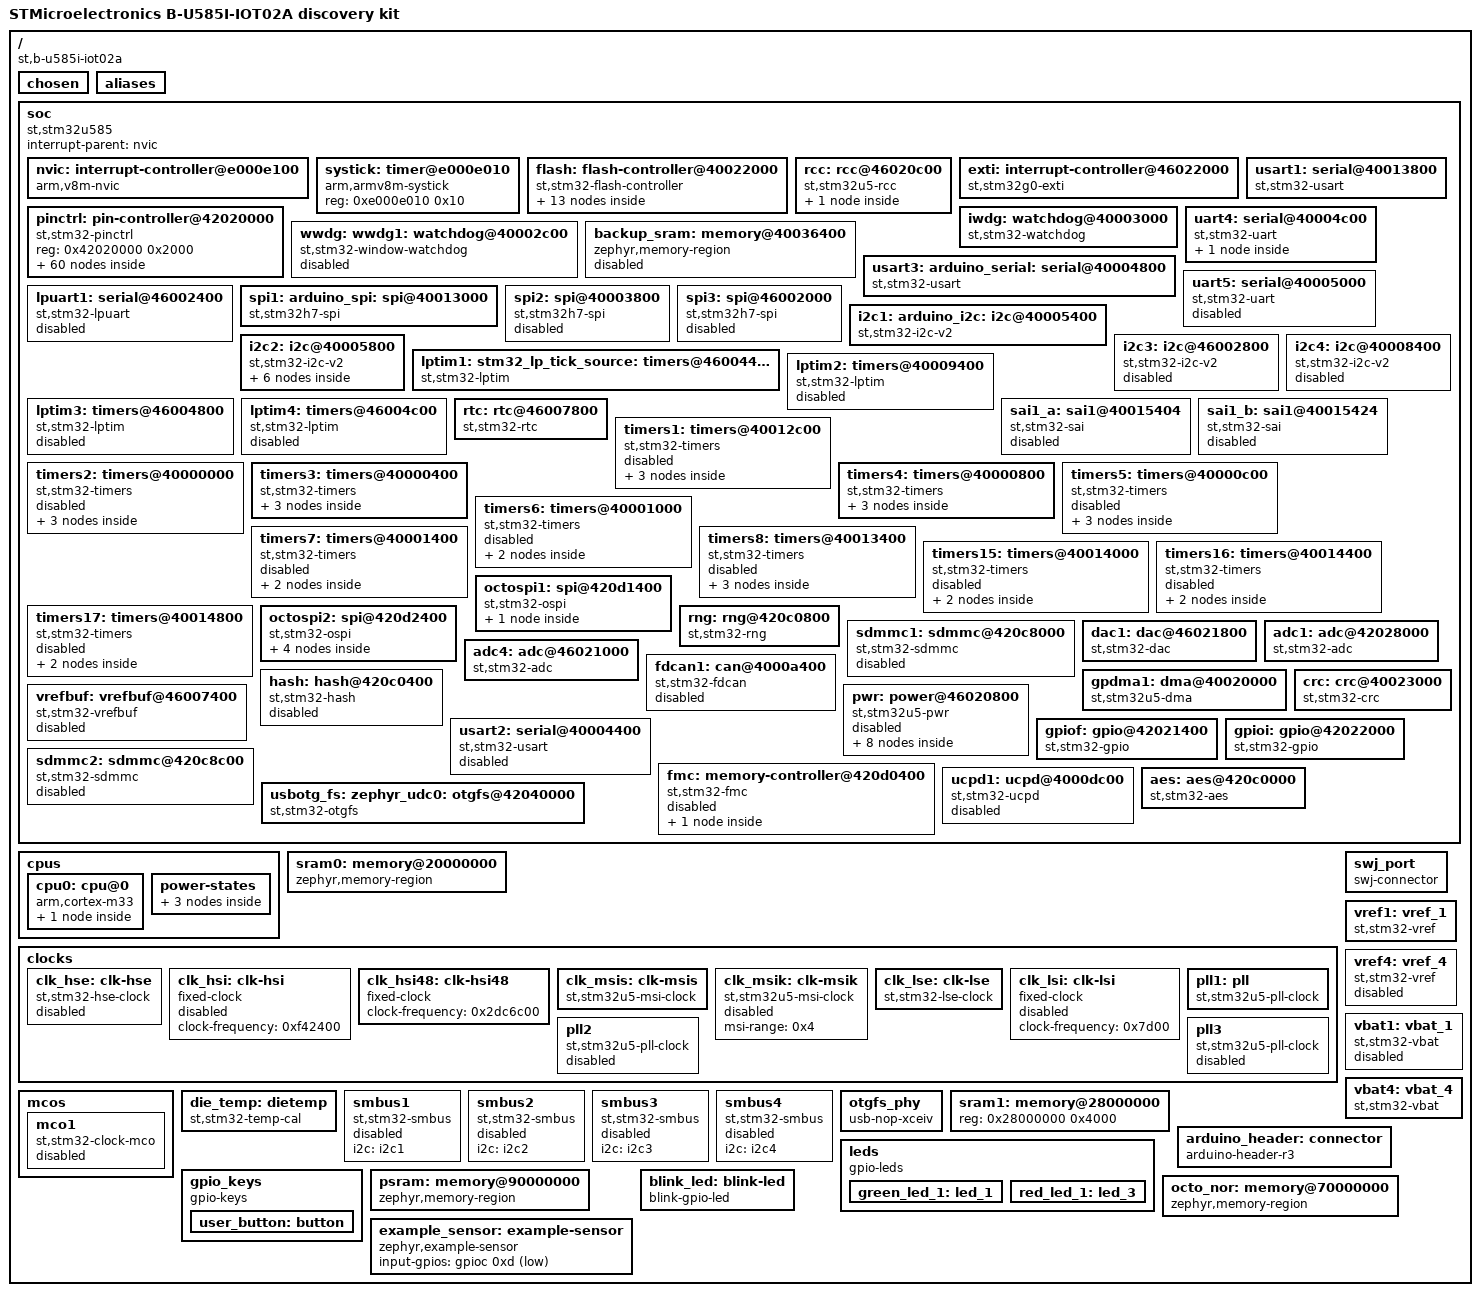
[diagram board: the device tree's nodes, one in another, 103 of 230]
/dts-v1/;

/* node '/' defined in zephyr/dts/common/skeleton.dtsi:9 */
/ {
	#address-cells = < 0x1 >;                                  /* in zephyr/dts/common/skeleton.dtsi:10 */
	#size-cells = < 0x1 >;                                     /* in zephyr/dts/common/skeleton.dtsi:11 */
	model = "STMicroelectronics B-U585I-IOT02A discovery kit"; /* in zephyr/boards/st/b_u585i_iot02a/b_u585i_iot02a.dts:13 */
	compatible = "st,b-u585i-iot02a";                          /* in zephyr/boards/st/b_u585i_iot02a/b_u585i_iot02a.dts:14 */

	/* node '/chosen' defined in zephyr/dts/common/skeleton.dtsi:13 */
	chosen {
		zephyr,crc = &crc;                        /* in zephyr/dts/arm/st/u5/stm32u5.dtsi:27 */
		zephyr,entropy = &rng;                    /* in zephyr/dts/arm/st/u5/stm32u5.dtsi:28 */
		zephyr,flash-controller = &flash;         /* in zephyr/dts/arm/st/u5/stm32u5.dtsi:29 */
		zephyr,console = &usart1;                 /* in zephyr/boards/st/b_u585i_iot02a/b_u585i_iot02a.dts:17 */
		zephyr,shell-uart = &usart1;              /* in zephyr/boards/st/b_u585i_iot02a/b_u585i_iot02a.dts:18 */
		zephyr,sram = &sram0;                     /* in zephyr/boards/st/b_u585i_iot02a/b_u585i_iot02a.dts:19 */
		zephyr,flash = &flash0;                   /* in zephyr/boards/st/b_u585i_iot02a/b_u585i_iot02a.dts:20 */
		zephyr,code-partition = &slot0_partition; /* in zephyr/boards/st/b_u585i_iot02a/b_u585i_iot02a.dts:21 */
		zephyr,bt-hci = &bt_hci_uart;             /* in zephyr/boards/st/b_u585i_iot02a/b_u585i_iot02a.dts:22 */
	};

	/* node '/aliases' defined in zephyr/dts/common/skeleton.dtsi:15 */
	aliases {
		watchdog0 = &iwdg;     /* in zephyr/boards/st/b_u585i_iot02a/b_u585i_iot02a-common.dtsi:41 */
		volt-sensor0 = &vref1; /* in zephyr/boards/st/b_u585i_iot02a/b_u585i_iot02a-common.dtsi:43 */
		volt-sensor1 = &vbat4; /* in zephyr/boards/st/b_u585i_iot02a/b_u585i_iot02a-common.dtsi:44 */
		eeprom-0 = &eeprom0;   /* in zephyr/boards/st/b_u585i_iot02a/b_u585i_iot02a-common.dtsi:45 */
		led0 = &green_led_1;   /* in zephyr/boards/st/b_u585i_iot02a/b_u585i_iot02a.dts:26 */
		led1 = &red_led_1;     /* in zephyr/boards/st/b_u585i_iot02a/b_u585i_iot02a.dts:27 */
		rtc = &rtc;            /* in zephyr/boards/st/b_u585i_iot02a/b_u585i_iot02a.dts:28 */
		sw0 = &user_button;    /* in zephyr/boards/st/b_u585i_iot02a/b_u585i_iot02a.dts:29 */
		die-temp0 = &die_temp; /* in zephyr/boards/st/b_u585i_iot02a/b_u585i_iot02a.dts:30 */
	};

	/* node '/soc' defined in zephyr/dts/arm/armv8-m.dtsi:6 */
	soc {
		#address-cells = < 0x1 >;     /* in zephyr/dts/arm/armv8-m.dtsi:7 */
		#size-cells = < 0x1 >;        /* in zephyr/dts/arm/armv8-m.dtsi:8 */
		interrupt-parent = < &nvic >; /* in zephyr/dts/arm/armv8-m.dtsi:10 */
		ranges;                       /* in zephyr/dts/arm/armv8-m.dtsi:11 */
		compatible = "st,stm32u585",
		             "st,stm32u5",
		             "simple-bus";    /* in zephyr/dts/arm/st/u5/stm32u585.dtsi:13 */

		/* node '/soc/interrupt-controller@e000e100' defined in zephyr/dts/arm/armv8-m.dtsi:13 */
		nvic: interrupt-controller@e000e100 {
			#address-cells = < 0x1 >;            /* in zephyr/dts/arm/armv8-m.dtsi:14 */
			compatible = "arm,v8m-nvic";         /* in zephyr/dts/arm/armv8-m.dtsi:15 */
			reg = < 0xe000e100 0xc00 >;          /* in zephyr/dts/arm/armv8-m.dtsi:16 */
			interrupt-controller;                /* in zephyr/dts/arm/armv8-m.dtsi:17 */
			#interrupt-cells = < 0x2 >;          /* in zephyr/dts/arm/armv8-m.dtsi:18 */
			arm,num-irq-priority-bits = < 0x4 >; /* in zephyr/dts/arm/st/u5/stm32u5.dtsi:1148 */
			phandle = < 0x1 >;                   /* in zephyr/dts/arm/armv8-m.dtsi:10 */
		};

		/* node '/soc/timer@e000e010' defined in zephyr/dts/arm/armv8-m.dtsi:21 */
		systick: timer@e000e010 {
			compatible = "arm,armv8m-systick"; /* in zephyr/dts/arm/armv8-m.dtsi:22 */
			reg = < 0xe000e010 0x10 >;         /* in zephyr/dts/arm/armv8-m.dtsi:23 */
		};

		/* node '/soc/flash-controller@40022000' defined in zephyr/dts/arm/st/u5/stm32u5.dtsi:165 */
		flash: flash-controller@40022000 {
			compatible = "st,stm32-flash-controller",
			             "st,stm32l5-flash-controller"; /* in zephyr/dts/arm/st/u5/stm32u5.dtsi:166 */
			reg = < 0x40022000 0x400 >;                 /* in zephyr/dts/arm/st/u5/stm32u5.dtsi:167 */
			interrupts = < 0x6 0x0 >;                   /* in zephyr/dts/arm/st/u5/stm32u5.dtsi:168 */
			#address-cells = < 0x1 >;                   /* in zephyr/dts/arm/st/u5/stm32u5.dtsi:170 */
			#size-cells = < 0x1 >;                      /* in zephyr/dts/arm/st/u5/stm32u5.dtsi:171 */
			ranges;                                     /* in zephyr/dts/arm/st/u5/stm32u5.dtsi:172 */

			/* node '/soc/flash-controller@40022000/flash@8000000' defined in zephyr/dts/arm/st/u5/stm32u5.dtsi:174 */
			flash0: flash@8000000 {
				compatible = "st,stm32-nv-flash",
				             "soc-nv-flash";         /* in zephyr/dts/arm/st/u5/stm32u5.dtsi:175 */
				#address-cells = < 0x1 >;            /* in zephyr/dts/arm/st/u5/stm32u5.dtsi:176 */
				#size-cells = < 0x1 >;               /* in zephyr/dts/arm/st/u5/stm32u5.dtsi:177 */
				write-block-size = < 0x10 >;         /* in zephyr/dts/arm/st/u5/stm32u5.dtsi:178 */
				erase-block-size = < 0x2000 >;       /* in zephyr/dts/arm/st/u5/stm32u5.dtsi:179 */
				max-erase-time = < 0x5 >;            /* in zephyr/dts/arm/st/u5/stm32u5.dtsi:181 */
				reg = < 0x8000000 0x200000 >;        /* in zephyr/dts/arm/st/u5/stm32u585Xi.dtsi:13 */
				ranges = < 0x0 0x8000000 0x200000 >; /* in zephyr/dts/arm/st/u5/stm32u585Xi.dtsi:14 */

				/* node '/soc/flash-controller@40022000/flash@8000000/partitions' defined in zephyr/boards/st/b_u585i_iot02a/b_u585i_iot02a.dts:43 */
				partitions {
					#address-cells = < 0x1 >; /* in zephyr/boards/st/b_u585i_iot02a/b_u585i_iot02a.dts:44 */
					#size-cells = < 0x1 >;    /* in zephyr/boards/st/b_u585i_iot02a/b_u585i_iot02a.dts:45 */
					ranges;                   /* in zephyr/boards/st/b_u585i_iot02a/b_u585i_iot02a.dts:46 */

					/* node '/soc/flash-controller@40022000/flash@8000000/partitions/partition@0' defined in zephyr/boards/st/b_u585i_iot02a/b_u585i_iot02a.dts:53 */
					boot_partition: partition@0 {
						compatible = "zephyr,mapped-partition"; /* in zephyr/boards/st/b_u585i_iot02a/b_u585i_iot02a.dts:54 */
						label = "mcuboot";                      /* in zephyr/boards/st/b_u585i_iot02a/b_u585i_iot02a.dts:55 */
						reg = < 0x0 0x10000 >;                  /* in zephyr/boards/st/b_u585i_iot02a/b_u585i_iot02a.dts:56 */
					};

					/* node '/soc/flash-controller@40022000/flash@8000000/partitions/partition@10000' defined in zephyr/boards/st/b_u585i_iot02a/b_u585i_iot02a.dts:59 */
					slot0_partition: partition@10000 {
						compatible = "zephyr,mapped-partition"; /* in zephyr/boards/st/b_u585i_iot02a/b_u585i_iot02a.dts:60 */
						label = "image-0";                      /* in zephyr/boards/st/b_u585i_iot02a/b_u585i_iot02a.dts:61 */
						reg = < 0x10000 0x68000 >;              /* in zephyr/boards/st/b_u585i_iot02a/b_u585i_iot02a.dts:62 */
					};

					/* node '/soc/flash-controller@40022000/flash@8000000/partitions/partition@78000' defined in zephyr/boards/st/b_u585i_iot02a/b_u585i_iot02a.dts:65 */
					slot1_partition: partition@78000 {
						compatible = "zephyr,mapped-partition"; /* in zephyr/boards/st/b_u585i_iot02a/b_u585i_iot02a.dts:66 */
						label = "image-1";                      /* in zephyr/boards/st/b_u585i_iot02a/b_u585i_iot02a.dts:67 */
						reg = < 0x78000 0x68000 >;              /* in zephyr/boards/st/b_u585i_iot02a/b_u585i_iot02a.dts:68 */
					};

					/* node '/soc/flash-controller@40022000/flash@8000000/partitions/partition@e0000' defined in zephyr/boards/st/b_u585i_iot02a/b_u585i_iot02a.dts:71 */
					scratch_partition: partition@e0000 {
						compatible = "zephyr,mapped-partition"; /* in zephyr/boards/st/b_u585i_iot02a/b_u585i_iot02a.dts:72 */
						label = "image-scratch";                /* in zephyr/boards/st/b_u585i_iot02a/b_u585i_iot02a.dts:73 */
						reg = < 0xe0000 0x10000 >;              /* in zephyr/boards/st/b_u585i_iot02a/b_u585i_iot02a.dts:74 */
					};

					/* node '/soc/flash-controller@40022000/flash@8000000/partitions/partition@f0000' defined in zephyr/boards/st/b_u585i_iot02a/b_u585i_iot02a.dts:77 */
					storage_partition: partition@f0000 {
						compatible = "zephyr,mapped-partition"; /* in zephyr/boards/st/b_u585i_iot02a/b_u585i_iot02a.dts:78 */
						label = "storage";                      /* in zephyr/boards/st/b_u585i_iot02a/b_u585i_iot02a.dts:79 */
						reg = < 0xf0000 0x10000 >;              /* in zephyr/boards/st/b_u585i_iot02a/b_u585i_iot02a.dts:80 */
					};
				};
			};

			/* node '/soc/flash-controller@40022000/flash@bfa0000' defined in zephyr/dts/arm/st/u5/stm32u5.dtsi:184 */
			st_nvm_user_otp: flash@bfa0000 {
				compatible = "st,stm32-nvm-otp"; /* in zephyr/dts/arm/st/u5/stm32u5.dtsi:185 */
				reg = < 0xbfa0000 0x200 >;       /* in zephyr/dts/arm/st/u5/stm32u5.dtsi:186 */
				status = "disabled";             /* in zephyr/dts/arm/st/u5/stm32u5.dtsi:187 */
			};

			/* node '/soc/flash-controller@40022000/flash@bfa0500' defined in zephyr/dts/arm/st/u5/stm32u5.dtsi:191 */
			flash@bfa0500 {
				compatible = "st,stm32-nvm-otp"; /* in zephyr/dts/arm/st/u5/stm32u5.dtsi:192 */
				reg = < 0xbfa0500 0x1b00 >;      /* in zephyr/dts/arm/st/u5/stm32u5.dtsi:193 */

				/* node '/soc/flash-controller@40022000/flash@bfa0500/nvmem-layout' defined in zephyr/dts/arm/st/u5/stm32u5.dtsi:195 */
				nvmem-layout {
					compatible = "fixed-layout"; /* in zephyr/dts/arm/st/u5/stm32u5.dtsi:196 */
					#address-cells = < 0x1 >;    /* in zephyr/dts/arm/st/u5/stm32u5.dtsi:197 */
					#size-cells = < 0x1 >;       /* in zephyr/dts/arm/st/u5/stm32u5.dtsi:198 */

					/* node '/soc/flash-controller@40022000/flash@bfa0500/nvmem-layout/ts-cal1@210' defined in zephyr/dts/arm/st/u5/stm32u5.dtsi:200 */
					ts_cal1_otp: ts-cal1@210 {
						reg = < 0x210 0x2 >;         /* in zephyr/dts/arm/st/u5/stm32u5.dtsi:201 */
						#nvmem-cell-cells = < 0x0 >; /* in zephyr/dts/arm/st/u5/stm32u5.dtsi:202 */
						read-only;                   /* in zephyr/dts/arm/st/u5/stm32u5.dtsi:203 */
						phandle = < 0x47 >;          /* in zephyr/dts/arm/st/u5/stm32u5.dtsi:1072 */
					};

					/* node '/soc/flash-controller@40022000/flash@bfa0500/nvmem-layout/ts-cal2@242' defined in zephyr/dts/arm/st/u5/stm32u5.dtsi:206 */
					ts_cal2_otp: ts-cal2@242 {
						reg = < 0x242 0x2 >;         /* in zephyr/dts/arm/st/u5/stm32u5.dtsi:207 */
						#nvmem-cell-cells = < 0x0 >; /* in zephyr/dts/arm/st/u5/stm32u5.dtsi:208 */
						read-only;                   /* in zephyr/dts/arm/st/u5/stm32u5.dtsi:209 */
						phandle = < 0x48 >;          /* in zephyr/dts/arm/st/u5/stm32u5.dtsi:1072 */
					};

					/* node '/soc/flash-controller@40022000/flash@bfa0500/nvmem-layout/vrefint@2a5' defined in zephyr/dts/arm/st/u5/stm32u5.dtsi:212 */
					vrefint_otp: vrefint@2a5 {
						reg = < 0x2a5 0x2 >;         /* in zephyr/dts/arm/st/u5/stm32u5.dtsi:213 */
						#nvmem-cell-cells = < 0x0 >; /* in zephyr/dts/arm/st/u5/stm32u5.dtsi:214 */
						read-only;                   /* in zephyr/dts/arm/st/u5/stm32u5.dtsi:215 */
						phandle = < 0x4a >;          /* in zephyr/dts/arm/st/u5/stm32u5.dtsi:1084 */
					};
				};
			};
		};

		/* node '/soc/rcc@46020c00' defined in zephyr/dts/arm/st/u5/stm32u5.dtsi:221 */
		rcc: rcc@46020c00 {
			compatible = "st,stm32u5-rcc";   /* in zephyr/dts/arm/st/u5/stm32u5.dtsi:222 */
			clocks-controller;               /* in zephyr/dts/arm/st/u5/stm32u5.dtsi:223 */
			#clock-cells = < 0x2 >;          /* in zephyr/dts/arm/st/u5/stm32u5.dtsi:224 */
			reg = < 0x46020c00 0x400 >;      /* in zephyr/dts/arm/st/u5/stm32u5.dtsi:225 */
			clocks = < &pll1 >;              /* in zephyr/boards/st/b_u585i_iot02a/b_u585i_iot02a-common.dtsi:80 */
			clock-frequency = < 0x9896800 >; /* in zephyr/boards/st/b_u585i_iot02a/b_u585i_iot02a-common.dtsi:81 */
			ahb-prescaler = < 0x1 >;         /* in zephyr/boards/st/b_u585i_iot02a/b_u585i_iot02a-common.dtsi:82 */
			apb1-prescaler = < 0x1 >;        /* in zephyr/boards/st/b_u585i_iot02a/b_u585i_iot02a-common.dtsi:83 */
			apb2-prescaler = < 0x1 >;        /* in zephyr/boards/st/b_u585i_iot02a/b_u585i_iot02a-common.dtsi:84 */
			apb3-prescaler = < 0x1 >;        /* in zephyr/boards/st/b_u585i_iot02a/b_u585i_iot02a-common.dtsi:85 */
			phandle = < 0x3 >;               /* in zephyr/dts/arm/st/u5/stm32u5.dtsi:239 */

			/* node '/soc/rcc@46020c00/reset-controller' defined in zephyr/dts/arm/st/u5/stm32u5.dtsi:227 */
			rctl: reset-controller {
				compatible = "st,stm32-rcc-rctl"; /* in zephyr/dts/arm/st/u5/stm32u5.dtsi:228 */
				#reset-cells = < 0x1 >;           /* in zephyr/dts/arm/st/u5/stm32u5.dtsi:229 */
				phandle = < 0x4 >;                /* in zephyr/dts/arm/st/u5/stm32u5.dtsi:346 */
			};
		};

		/* node '/soc/interrupt-controller@46022000' defined in zephyr/dts/arm/st/u5/stm32u5.dtsi:233 */
		exti: interrupt-controller@46022000 {
			compatible = "st,stm32g0-exti",
			             "st,stm32-exti";   /* in zephyr/dts/arm/st/u5/stm32u5.dtsi:234 */
			interrupt-controller;           /* in zephyr/dts/arm/st/u5/stm32u5.dtsi:235 */
			#interrupt-cells = < 0x1 >;     /* in zephyr/dts/arm/st/u5/stm32u5.dtsi:236 */
			#address-cells = < 0x0 >;       /* in zephyr/dts/arm/st/u5/stm32u5.dtsi:237 */
			reg = < 0x46022000 0x400 >;     /* in zephyr/dts/arm/st/u5/stm32u5.dtsi:238 */
			clocks = < &rcc 0xa8 0x2 >;     /* in zephyr/dts/arm/st/u5/stm32u5.dtsi:239 */
			num-lines = < 0x20 >;           /* in zephyr/dts/arm/st/u5/stm32u5.dtsi:240 */
			interrupts = < 0xb 0x0 >,
			             < 0xc 0x0 >,
			             < 0xd 0x0 >,
			             < 0xe 0x0 >,
			             < 0xf 0x0 >,
			             < 0x10 0x0 >,
			             < 0x11 0x0 >,
			             < 0x12 0x0 >,
			             < 0x13 0x0 >,
			             < 0x14 0x0 >,
			             < 0x15 0x0 >,
			             < 0x16 0x0 >,
			             < 0x17 0x0 >,
			             < 0x18 0x0 >,
			             < 0x19 0x0 >,
			             < 0x1a 0x0 >;      /* in zephyr/dts/arm/st/u5/stm32u5.dtsi:241 */
			interrupt-names = "line0",
			                  "line1",
			                  "line2",
			                  "line3",
			                  "line4",
			                  "line5",
			                  "line6",
			                  "line7",
			                  "line8",
			                  "line9",
			                  "line10",
			                  "line11",
			                  "line12",
			                  "line13",
			                  "line14",
			                  "line15";     /* in zephyr/dts/arm/st/u5/stm32u5.dtsi:245 */
			line-ranges = < 0x0 0x1 >,
			              < 0x1 0x1 >,
			              < 0x2 0x1 >,
			              < 0x3 0x1 >,
			              < 0x4 0x1 >,
			              < 0x5 0x1 >,
			              < 0x6 0x1 >,
			              < 0x7 0x1 >,
			              < 0x8 0x1 >,
			              < 0x9 0x1 >,
			              < 0xa 0x1 >,
			              < 0xb 0x1 >,
			              < 0xc 0x1 >,
			              < 0xd 0x1 >,
			              < 0xe 0x1 >,
			              < 0xf 0x1 >;      /* in zephyr/dts/arm/st/u5/stm32u5.dtsi:249 */
		};

		/* node '/soc/pin-controller@42020000' defined in zephyr/dts/arm/st/u5/stm32u5.dtsi:255 */
		pinctrl: pin-controller@42020000 {
			compatible = "st,stm32-pinctrl"; /* in zephyr/dts/arm/st/u5/stm32u5.dtsi:256 */
			#address-cells = < 0x1 >;        /* in zephyr/dts/arm/st/u5/stm32u5.dtsi:257 */
			#size-cells = < 0x1 >;           /* in zephyr/dts/arm/st/u5/stm32u5.dtsi:258 */
			reg = < 0x42020000 0x2000 >;     /* in zephyr/dts/arm/st/u5/stm32u5.dtsi:259 */

			/* node '/soc/pin-controller@42020000/gpio@42020000' defined in zephyr/dts/arm/st/u5/stm32u5.dtsi:261 */
			gpioa: gpio@42020000 {
				compatible = "st,stm32-gpio"; /* in zephyr/dts/arm/st/u5/stm32u5.dtsi:262 */
				gpio-controller;              /* in zephyr/dts/arm/st/u5/stm32u5.dtsi:263 */
				#gpio-cells = < 0x2 >;        /* in zephyr/dts/arm/st/u5/stm32u5.dtsi:264 */
				reg = < 0x42020000 0x400 >;   /* in zephyr/dts/arm/st/u5/stm32u5.dtsi:265 */
				clocks = < &rcc 0x8c 0x1 >;   /* in zephyr/dts/arm/st/u5/stm32u5.dtsi:266 */
				phandle = < 0x32 >;           /* in zephyr/dts/arm/st/u5/stm32u5.dtsi:997 */
			};

			/* node '/soc/pin-controller@42020000/gpio@42020400' defined in zephyr/dts/arm/st/u5/stm32u5.dtsi:269 */
			gpiob: gpio@42020400 {
				compatible = "st,stm32-gpio"; /* in zephyr/dts/arm/st/u5/stm32u5.dtsi:270 */
				gpio-controller;              /* in zephyr/dts/arm/st/u5/stm32u5.dtsi:271 */
				#gpio-cells = < 0x2 >;        /* in zephyr/dts/arm/st/u5/stm32u5.dtsi:272 */
				reg = < 0x42020400 0x400 >;   /* in zephyr/dts/arm/st/u5/stm32u5.dtsi:273 */
				clocks = < &rcc 0x8c 0x2 >;   /* in zephyr/dts/arm/st/u5/stm32u5.dtsi:274 */
				phandle = < 0x33 >;           /* in zephyr/dts/arm/st/u5/stm32u5.dtsi:997 */
			};

			/* node '/soc/pin-controller@42020000/gpio@42020800' defined in zephyr/dts/arm/st/u5/stm32u5.dtsi:277 */
			gpioc: gpio@42020800 {
				compatible = "st,stm32-gpio"; /* in zephyr/dts/arm/st/u5/stm32u5.dtsi:278 */
				gpio-controller;              /* in zephyr/dts/arm/st/u5/stm32u5.dtsi:279 */
				#gpio-cells = < 0x2 >;        /* in zephyr/dts/arm/st/u5/stm32u5.dtsi:280 */
				reg = < 0x42020800 0x400 >;   /* in zephyr/dts/arm/st/u5/stm32u5.dtsi:281 */
				clocks = < &rcc 0x8c 0x4 >;   /* in zephyr/dts/arm/st/u5/stm32u5.dtsi:282 */
				status = "okay";              /* in my-app/app/boards/b_u585i_iot02a.overlay:26 */
				phandle = < 0x34 >;           /* in zephyr/dts/arm/st/u5/stm32u5.dtsi:1004 */
			};

			/* node '/soc/pin-controller@42020000/gpio@42020c00' defined in zephyr/dts/arm/st/u5/stm32u5.dtsi:285 */
			gpiod: gpio@42020c00 {
				compatible = "st,stm32-gpio"; /* in zephyr/dts/arm/st/u5/stm32u5.dtsi:286 */
				gpio-controller;              /* in zephyr/dts/arm/st/u5/stm32u5.dtsi:287 */
				#gpio-cells = < 0x2 >;        /* in zephyr/dts/arm/st/u5/stm32u5.dtsi:288 */
				reg = < 0x42020c00 0x400 >;   /* in zephyr/dts/arm/st/u5/stm32u5.dtsi:289 */
				clocks = < &rcc 0x8c 0x8 >;   /* in zephyr/dts/arm/st/u5/stm32u5.dtsi:290 */
				phandle = < 0x13 >;           /* in zephyr/boards/st/b_u585i_iot02a/b_u585i_iot02a-common.dtsi:217 */
			};

			/* node '/soc/pin-controller@42020000/gpio@42021000' defined in zephyr/dts/arm/st/u5/stm32u5.dtsi:293 */
			gpioe: gpio@42021000 {
				compatible = "st,stm32-gpio"; /* in zephyr/dts/arm/st/u5/stm32u5.dtsi:294 */
				gpio-controller;              /* in zephyr/dts/arm/st/u5/stm32u5.dtsi:295 */
				#gpio-cells = < 0x2 >;        /* in zephyr/dts/arm/st/u5/stm32u5.dtsi:296 */
				reg = < 0x42021000 0x400 >;   /* in zephyr/dts/arm/st/u5/stm32u5.dtsi:297 */
				clocks = < &rcc 0x8c 0x10 >;  /* in zephyr/dts/arm/st/u5/stm32u5.dtsi:298 */
				phandle = < 0x14 >;           /* in zephyr/boards/st/b_u585i_iot02a/b_u585i_iot02a-common.dtsi:223 */
			};

			/* node '/soc/pin-controller@42020000/gpio@42021800' defined in zephyr/dts/arm/st/u5/stm32u5.dtsi:301 */
			gpiog: gpio@42021800 {
				compatible = "st,stm32-gpio"; /* in zephyr/dts/arm/st/u5/stm32u5.dtsi:302 */
				gpio-controller;              /* in zephyr/dts/arm/st/u5/stm32u5.dtsi:303 */
				#gpio-cells = < 0x2 >;        /* in zephyr/dts/arm/st/u5/stm32u5.dtsi:304 */
				reg = < 0x42021800 0x400 >;   /* in zephyr/dts/arm/st/u5/stm32u5.dtsi:305 */
				clocks = < &rcc 0x8c 0x40 >;  /* in zephyr/dts/arm/st/u5/stm32u5.dtsi:306 */
				phandle = < 0x15 >;           /* in zephyr/boards/st/b_u585i_iot02a/b_u585i_iot02a-common.dtsi:229 */
			};

			/* node '/soc/pin-controller@42020000/gpio@42021c00' defined in zephyr/dts/arm/st/u5/stm32u5.dtsi:309 */
			gpioh: gpio@42021c00 {
				compatible = "st,stm32-gpio"; /* in zephyr/dts/arm/st/u5/stm32u5.dtsi:310 */
				gpio-controller;              /* in zephyr/dts/arm/st/u5/stm32u5.dtsi:311 */
				#gpio-cells = < 0x2 >;        /* in zephyr/dts/arm/st/u5/stm32u5.dtsi:312 */
				reg = < 0x42021c00 0x400 >;   /* in zephyr/dts/arm/st/u5/stm32u5.dtsi:313 */
				clocks = < &rcc 0x8c 0x80 >;  /* in zephyr/dts/arm/st/u5/stm32u5.dtsi:314 */
				phandle = < 0x50 >;           /* in zephyr/boards/st/b_u585i_iot02a/b_u585i_iot02a-common.dtsi:20 */
			};

			/* node '/soc/pin-controller@42020000/adc1_in15_pb0' defined in modules/hal/stm32/dts/st/u5/stm32u585aiixq-pinctrl.dtsi:45 */
			adc1_in15_pb0: adc1_in15_pb0 {
				pinmux = < 0x210 >; /* in modules/hal/stm32/dts/st/u5/stm32u585aiixq-pinctrl.dtsi:46 */
				phandle = < 0x30 >; /* in zephyr/boards/st/b_u585i_iot02a/b_u585i_iot02a-common.dtsi:259 */
			};

			/* node '/soc/pin-controller@42020000/adc4_in19_pb1' defined in modules/hal/stm32/dts/st/u5/stm32u585aiixq-pinctrl.dtsi:101 */
			adc4_in19_pb1: adc4_in19_pb1 {
				pinmux = < 0x230 >; /* in modules/hal/stm32/dts/st/u5/stm32u585aiixq-pinctrl.dtsi:102 */
				phandle = < 0x31 >; /* in zephyr/boards/st/b_u585i_iot02a/b_u585i_iot02a-common.dtsi:267 */
			};

			/* node '/soc/pin-controller@42020000/analog_pa13' defined in modules/hal/stm32/dts/st/u5/stm32u585aiixq-pinctrl.dtsi:211 */
			analog_pa13: analog_pa13 {
				pinmux = < 0x1b0 >; /* in modules/hal/stm32/dts/st/u5/stm32u585aiixq-pinctrl.dtsi:212 */
				phandle = < 0x42 >; /* in zephyr/dts/arm/st/u5/stm32u5.dtsi:1065 */
			};

			/* node '/soc/pin-controller@42020000/analog_pa14' defined in modules/hal/stm32/dts/st/u5/stm32u585aiixq-pinctrl.dtsi:215 */
			analog_pa14: analog_pa14 {
				pinmux = < 0x1d0 >; /* in modules/hal/stm32/dts/st/u5/stm32u585aiixq-pinctrl.dtsi:216 */
				phandle = < 0x43 >; /* in zephyr/dts/arm/st/u5/stm32u5.dtsi:1065 */
			};

			/* node '/soc/pin-controller@42020000/analog_pa15' defined in modules/hal/stm32/dts/st/u5/stm32u585aiixq-pinctrl.dtsi:219 */
			analog_pa15: analog_pa15 {
				pinmux = < 0x1f0 >; /* in modules/hal/stm32/dts/st/u5/stm32u585aiixq-pinctrl.dtsi:220 */
				phandle = < 0x44 >; /* in zephyr/dts/arm/st/u5/stm32u5.dtsi:1065 */
			};

			/* node '/soc/pin-controller@42020000/analog_pb3' defined in modules/hal/stm32/dts/st/u5/stm32u585aiixq-pinctrl.dtsi:235 */
			analog_pb3: analog_pb3 {
				pinmux = < 0x270 >; /* in modules/hal/stm32/dts/st/u5/stm32u585aiixq-pinctrl.dtsi:236 */
				phandle = < 0x45 >; /* in zephyr/dts/arm/st/u5/stm32u5.dtsi:1065 */
			};

			/* node '/soc/pin-controller@42020000/analog_pb4' defined in modules/hal/stm32/dts/st/u5/stm32u585aiixq-pinctrl.dtsi:239 */
			analog_pb4: analog_pb4 {
				pinmux = < 0x290 >; /* in modules/hal/stm32/dts/st/u5/stm32u585aiixq-pinctrl.dtsi:240 */
				phandle = < 0x46 >; /* in zephyr/dts/arm/st/u5/stm32u5.dtsi:1065 */
			};

			/* node '/soc/pin-controller@42020000/dac1_out1_pa4' defined in modules/hal/stm32/dts/st/u5/stm32u585aiixq-pinctrl.dtsi:749 */
			dac1_out1_pa4: dac1_out1_pa4 {
				pinmux = < 0x90 >;  /* in modules/hal/stm32/dts/st/u5/stm32u585aiixq-pinctrl.dtsi:750 */
				phandle = < 0x2f >; /* in zephyr/boards/st/b_u585i_iot02a/b_u585i_iot02a-common.dtsi:279 */
			};

			/* node '/soc/pin-controller@42020000/i2c1_scl_pb8' defined in modules/hal/stm32/dts/st/u5/stm32u585aiixq-pinctrl.dtsi:1405 */
			i2c1_scl_pb8: i2c1_scl_pb8 {
				pinmux = < 0x304 >; /* in modules/hal/stm32/dts/st/u5/stm32u585aiixq-pinctrl.dtsi:1406 */
				bias-pull-up;       /* in modules/hal/stm32/dts/st/u5/stm32u585aiixq-pinctrl.dtsi:1407 */
				drive-open-drain;   /* in modules/hal/stm32/dts/st/u5/stm32u585aiixq-pinctrl.dtsi:1408 */
				phandle = < 0xf >;  /* in zephyr/boards/st/b_u585i_iot02a/b_u585i_iot02a-common.dtsi:196 */
			};

			/* node '/soc/pin-controller@42020000/i2c2_scl_ph4' defined in modules/hal/stm32/dts/st/u5/stm32u585aiixq-pinctrl.dtsi:1429 */
			i2c2_scl_ph4: i2c2_scl_ph4 {
				pinmux = < 0xe84 >; /* in modules/hal/stm32/dts/st/u5/stm32u585aiixq-pinctrl.dtsi:1430 */
				bias-pull-up;       /* in modules/hal/stm32/dts/st/u5/stm32u585aiixq-pinctrl.dtsi:1431 */
				drive-open-drain;   /* in modules/hal/stm32/dts/st/u5/stm32u585aiixq-pinctrl.dtsi:1432 */
				phandle = < 0x11 >; /* in zephyr/boards/st/b_u585i_iot02a/b_u585i_iot02a-common.dtsi:203 */
			};

			/* node '/soc/pin-controller@42020000/i2c1_sda_pb9' defined in modules/hal/stm32/dts/st/u5/stm32u585aiixq-pinctrl.dtsi:1497 */
			i2c1_sda_pb9: i2c1_sda_pb9 {
				pinmux = < 0x324 >; /* in modules/hal/stm32/dts/st/u5/stm32u585aiixq-pinctrl.dtsi:1498 */
				bias-pull-up;       /* in modules/hal/stm32/dts/st/u5/stm32u585aiixq-pinctrl.dtsi:1499 */
				drive-open-drain;   /* in modules/hal/stm32/dts/st/u5/stm32u585aiixq-pinctrl.dtsi:1500 */
				phandle = < 0x10 >; /* in zephyr/boards/st/b_u585i_iot02a/b_u585i_iot02a-common.dtsi:196 */
			};

			/* node '/soc/pin-controller@42020000/i2c2_sda_ph5' defined in modules/hal/stm32/dts/st/u5/stm32u585aiixq-pinctrl.dtsi:1521 */
			i2c2_sda_ph5: i2c2_sda_ph5 {
				pinmux = < 0xea4 >; /* in modules/hal/stm32/dts/st/u5/stm32u585aiixq-pinctrl.dtsi:1522 */
				bias-pull-up;       /* in modules/hal/stm32/dts/st/u5/stm32u585aiixq-pinctrl.dtsi:1523 */
				drive-open-drain;   /* in modules/hal/stm32/dts/st/u5/stm32u585aiixq-pinctrl.dtsi:1524 */
				phandle = < 0x12 >; /* in zephyr/boards/st/b_u585i_iot02a/b_u585i_iot02a-common.dtsi:203 */
			};

			/* node '/soc/pin-controller@42020000/debug_jtms_swdio_pa13' defined in modules/hal/stm32/dts/st/u5/stm32u585aiixq-pinctrl.dtsi:1644 */
			debug_jtms_swdio_pa13: debug_jtms_swdio_pa13 {
				pinmux = < 0x1a0 >; /* in modules/hal/stm32/dts/st/u5/stm32u585aiixq-pinctrl.dtsi:1645 */
				phandle = < 0x3d >; /* in zephyr/dts/arm/st/u5/stm32u5.dtsi:1062 */
			};

			/* node '/soc/pin-controller@42020000/debug_jtck_swclk_pa14' defined in modules/hal/stm32/dts/st/u5/stm32u585aiixq-pinctrl.dtsi:1648 */
			debug_jtck_swclk_pa14: debug_jtck_swclk_pa14 {
				pinmux = < 0x1c0 >; /* in modules/hal/stm32/dts/st/u5/stm32u585aiixq-pinctrl.dtsi:1649 */
				phandle = < 0x3e >; /* in zephyr/dts/arm/st/u5/stm32u5.dtsi:1062 */
			};

			/* node '/soc/pin-controller@42020000/debug_jtdi_pa15' defined in modules/hal/stm32/dts/st/u5/stm32u585aiixq-pinctrl.dtsi:1652 */
			debug_jtdi_pa15: debug_jtdi_pa15 {
				pinmux = < 0x1e0 >; /* in modules/hal/stm32/dts/st/u5/stm32u585aiixq-pinctrl.dtsi:1653 */
				phandle = < 0x3f >; /* in zephyr/dts/arm/st/u5/stm32u5.dtsi:1062 */
			};

			/* node '/soc/pin-controller@42020000/debug_jtdo_swo_pb3' defined in modules/hal/stm32/dts/st/u5/stm32u585aiixq-pinctrl.dtsi:1656 */
			debug_jtdo_swo_pb3: debug_jtdo_swo_pb3 {
				pinmux = < 0x260 >; /* in modules/hal/stm32/dts/st/u5/stm32u585aiixq-pinctrl.dtsi:1657 */
				phandle = < 0x40 >; /* in zephyr/dts/arm/st/u5/stm32u5.dtsi:1062 */
			};

			/* node '/soc/pin-controller@42020000/debug_njtrst_pb4' defined in modules/hal/stm32/dts/st/u5/stm32u585aiixq-pinctrl.dtsi:1660 */
			debug_njtrst_pb4: debug_njtrst_pb4 {
				pinmux = < 0x280 >; /* in modules/hal/stm32/dts/st/u5/stm32u585aiixq-pinctrl.dtsi:1661 */
				phandle = < 0x41 >; /* in zephyr/dts/arm/st/u5/stm32u5.dtsi:1062 */
			};

			/* node '/soc/pin-controller@42020000/octospim_p1_clk_pb10' defined in modules/hal/stm32/dts/st/u5/stm32u585aiixq-pinctrl.dtsi:1944 */
			octospim_p1_clk_pb10: octospim_p1_clk_pb10 {
				pinmux = < 0x34a >;            /* in modules/hal/stm32/dts/st/u5/stm32u585aiixq-pinctrl.dtsi:1945 */
				slew-rate = "very-high-speed"; /* in modules/hal/stm32/dts/st/u5/stm32u585aiixq-pinctrl.dtsi:1946 */
				phandle = < 0x19 >;            /* in zephyr/boards/st/b_u585i_iot02a/b_u585i_iot02a-common.dtsi:138 */
			};

			/* node '/soc/pin-controller@42020000/octospim_p1_ncs_pb11' defined in modules/hal/stm32/dts/st/u5/stm32u585aiixq-pinctrl.dtsi:1949 */
			octospim_p1_ncs_pb11: octospim_p1_ncs_pb11 {
				pinmux = < 0x36a >;            /* in modules/hal/stm32/dts/st/u5/stm32u585aiixq-pinctrl.dtsi:1950 */
				slew-rate = "very-high-speed"; /* in modules/hal/stm32/dts/st/u5/stm32u585aiixq-pinctrl.dtsi:1951 */
				phandle = < 0x1a >;            /* in zephyr/boards/st/b_u585i_iot02a/b_u585i_iot02a-common.dtsi:138 */
			};

			/* node '/soc/pin-controller@42020000/octospim_p1_io6_pc3' defined in modules/hal/stm32/dts/st/u5/stm32u585aiixq-pinctrl.dtsi:1974 */
			octospim_p1_io6_pc3: octospim_p1_io6_pc3 {
				pinmux = < 0x46a >;            /* in modules/hal/stm32/dts/st/u5/stm32u585aiixq-pinctrl.dtsi:1975 */
				slew-rate = "very-high-speed"; /* in modules/hal/stm32/dts/st/u5/stm32u585aiixq-pinctrl.dtsi:1976 */
				phandle = < 0x21 >;            /* in zephyr/boards/st/b_u585i_iot02a/b_u585i_iot02a-common.dtsi:138 */
			};

			/* node '/soc/pin-controller@42020000/octospim_p1_io7_pd7' defined in modules/hal/stm32/dts/st/u5/stm32u585aiixq-pinctrl.dtsi:2009 */
			octospim_p1_io7_pd7: octospim_p1_io7_pd7 {
				pinmux = < 0x6ea >;            /* in modules/hal/stm32/dts/st/u5/stm32u585aiixq-pinctrl.dtsi:2010 */
				slew-rate = "very-high-speed"; /* in modules/hal/stm32/dts/st/u5/stm32u585aiixq-pinctrl.dtsi:2011 */
				phandle = < 0x22 >;            /* in zephyr/boards/st/b_u585i_iot02a/b_u585i_iot02a-common.dtsi:138 */
			};

			/* node '/soc/pin-controller@42020000/octospim_p1_dqs_pe3' defined in modules/hal/stm32/dts/st/u5/stm32u585aiixq-pinctrl.dtsi:2014 */
			octospim_p1_dqs_pe3: octospim_p1_dqs_pe3 {
				pinmux = < 0x863 >;            /* in modules/hal/stm32/dts/st/u5/stm32u585aiixq-pinctrl.dtsi:2015 */
				slew-rate = "very-high-speed"; /* in modules/hal/stm32/dts/st/u5/stm32u585aiixq-pinctrl.dtsi:2016 */
				phandle = < 0x23 >;            /* in zephyr/boards/st/b_u585i_iot02a/b_u585i_iot02a-common.dtsi:138 */
			};

			/* node '/soc/pin-controller@42020000/octospim_p2_io0_pf0' defined in modules/hal/stm32/dts/st/u5/stm32u585aiixq-pinctrl.dtsi:2054 */
			octospim_p2_io0_pf0: octospim_p2_io0_pf0 {
				pinmux = < 0xa05 >;            /* in modules/hal/stm32/dts/st/u5/stm32u585aiixq-pinctrl.dtsi:2055 */
				slew-rate = "very-high-speed"; /* in modules/hal/stm32/dts/st/u5/stm32u585aiixq-pinctrl.dtsi:2056 */
				phandle = < 0x26 >;            /* in zephyr/boards/st/b_u585i_iot02a/b_u585i_iot02a-common.dtsi:161 */
			};

			/* node '/soc/pin-controller@42020000/octospim_p2_io1_pf1' defined in modules/hal/stm32/dts/st/u5/stm32u585aiixq-pinctrl.dtsi:2059 */
			octospim_p2_io1_pf1: octospim_p2_io1_pf1 {
				pinmux = < 0xa25 >;            /* in modules/hal/stm32/dts/st/u5/stm32u585aiixq-pinctrl.dtsi:2060 */
				slew-rate = "very-high-speed"; /* in modules/hal/stm32/dts/st/u5/stm32u585aiixq-pinctrl.dtsi:2061 */
				phandle = < 0x27 >;            /* in zephyr/boards/st/b_u585i_iot02a/b_u585i_iot02a-common.dtsi:161 */
			};

			/* node '/soc/pin-controller@42020000/octospim_p2_io2_pf2' defined in modules/hal/stm32/dts/st/u5/stm32u585aiixq-pinctrl.dtsi:2064 */
			octospim_p2_io2_pf2: octospim_p2_io2_pf2 {
				pinmux = < 0xa45 >;            /* in modules/hal/stm32/dts/st/u5/stm32u585aiixq-pinctrl.dtsi:2065 */
				slew-rate = "very-high-speed"; /* in modules/hal/stm32/dts/st/u5/stm32u585aiixq-pinctrl.dtsi:2066 */
				phandle = < 0x28 >;            /* in zephyr/boards/st/b_u585i_iot02a/b_u585i_iot02a-common.dtsi:161 */
			};

			/* node '/soc/pin-controller@42020000/octospim_p2_io3_pf3' defined in modules/hal/stm32/dts/st/u5/stm32u585aiixq-pinctrl.dtsi:2069 */
			octospim_p2_io3_pf3: octospim_p2_io3_pf3 {
				pinmux = < 0xa65 >;            /* in modules/hal/stm32/dts/st/u5/stm32u585aiixq-pinctrl.dtsi:2070 */
				slew-rate = "very-high-speed"; /* in modules/hal/stm32/dts/st/u5/stm32u585aiixq-pinctrl.dtsi:2071 */
				phandle = < 0x29 >;            /* in zephyr/boards/st/b_u585i_iot02a/b_u585i_iot02a-common.dtsi:161 */
			};

			/* node '/soc/pin-controller@42020000/octospim_p2_clk_pf4' defined in modules/hal/stm32/dts/st/u5/stm32u585aiixq-pinctrl.dtsi:2074 */
			octospim_p2_clk_pf4: octospim_p2_clk_pf4 {
				pinmux = < 0xa85 >;            /* in modules/hal/stm32/dts/st/u5/stm32u585aiixq-pinctrl.dtsi:2075 */
				slew-rate = "very-high-speed"; /* in modules/hal/stm32/dts/st/u5/stm32u585aiixq-pinctrl.dtsi:2076 */
				phandle = < 0x24 >;            /* in zephyr/boards/st/b_u585i_iot02a/b_u585i_iot02a-common.dtsi:161 */
			};

			/* node '/soc/pin-controller@42020000/octospim_p1_io3_pf6' defined in modules/hal/stm32/dts/st/u5/stm32u585aiixq-pinctrl.dtsi:2084 */
			octospim_p1_io3_pf6: octospim_p1_io3_pf6 {
				pinmux = < 0xaca >;            /* in modules/hal/stm32/dts/st/u5/stm32u585aiixq-pinctrl.dtsi:2085 */
				slew-rate = "very-high-speed"; /* in modules/hal/stm32/dts/st/u5/stm32u585aiixq-pinctrl.dtsi:2086 */
				phandle = < 0x1e >;            /* in zephyr/boards/st/b_u585i_iot02a/b_u585i_iot02a-common.dtsi:138 */
			};

			/* node '/soc/pin-controller@42020000/octospim_p1_io2_pf7' defined in modules/hal/stm32/dts/st/u5/stm32u585aiixq-pinctrl.dtsi:2094 */
			octospim_p1_io2_pf7: octospim_p1_io2_pf7 {
				pinmux = < 0xaea >;            /* in modules/hal/stm32/dts/st/u5/stm32u585aiixq-pinctrl.dtsi:2095 */
				slew-rate = "very-high-speed"; /* in modules/hal/stm32/dts/st/u5/stm32u585aiixq-pinctrl.dtsi:2096 */
				phandle = < 0x1d >;            /* in zephyr/boards/st/b_u585i_iot02a/b_u585i_iot02a-common.dtsi:138 */
			};

			/* node '/soc/pin-controller@42020000/octospim_p1_io0_pf8' defined in modules/hal/stm32/dts/st/u5/stm32u585aiixq-pinctrl.dtsi:2099 */
			octospim_p1_io0_pf8: octospim_p1_io0_pf8 {
				pinmux = < 0xb0a >;            /* in modules/hal/stm32/dts/st/u5/stm32u585aiixq-pinctrl.dtsi:2100 */
				slew-rate = "very-high-speed"; /* in modules/hal/stm32/dts/st/u5/stm32u585aiixq-pinctrl.dtsi:2101 */
				phandle = < 0x1b >;            /* in zephyr/boards/st/b_u585i_iot02a/b_u585i_iot02a-common.dtsi:138 */
			};

			/* node '/soc/pin-controller@42020000/octospim_p1_io1_pf9' defined in modules/hal/stm32/dts/st/u5/stm32u585aiixq-pinctrl.dtsi:2104 */
			octospim_p1_io1_pf9: octospim_p1_io1_pf9 {
				pinmux = < 0xb2a >;            /* in modules/hal/stm32/dts/st/u5/stm32u585aiixq-pinctrl.dtsi:2105 */
				slew-rate = "very-high-speed"; /* in modules/hal/stm32/dts/st/u5/stm32u585aiixq-pinctrl.dtsi:2106 */
				phandle = < 0x1c >;            /* in zephyr/boards/st/b_u585i_iot02a/b_u585i_iot02a-common.dtsi:138 */
			};

			/* node '/soc/pin-controller@42020000/octospim_p2_dqs_pf12' defined in modules/hal/stm32/dts/st/u5/stm32u585aiixq-pinctrl.dtsi:2119 */
			octospim_p2_dqs_pf12: octospim_p2_dqs_pf12 {
				pinmux = < 0xb85 >;            /* in modules/hal/stm32/dts/st/u5/stm32u585aiixq-pinctrl.dtsi:2120 */
				slew-rate = "very-high-speed"; /* in modules/hal/stm32/dts/st/u5/stm32u585aiixq-pinctrl.dtsi:2121 */
				phandle = < 0x2e >;            /* in zephyr/boards/st/b_u585i_iot02a/b_u585i_iot02a-common.dtsi:161 */
			};

			/* node '/soc/pin-controller@42020000/octospim_p1_io4_ph2' defined in modules/hal/stm32/dts/st/u5/stm32u585aiixq-pinctrl.dtsi:2164 */
			octospim_p1_io4_ph2: octospim_p1_io4_ph2 {
				pinmux = < 0xe43 >;            /* in modules/hal/stm32/dts/st/u5/stm32u585aiixq-pinctrl.dtsi:2165 */
				slew-rate = "very-high-speed"; /* in modules/hal/stm32/dts/st/u5/stm32u585aiixq-pinctrl.dtsi:2166 */
				phandle = < 0x1f >;            /* in zephyr/boards/st/b_u585i_iot02a/b_u585i_iot02a-common.dtsi:138 */
			};

			/* node '/soc/pin-controller@42020000/octospim_p2_io4_ph9' defined in modules/hal/stm32/dts/st/u5/stm32u585aiixq-pinctrl.dtsi:2189 */
			octospim_p2_io4_ph9: octospim_p2_io4_ph9 {
				pinmux = < 0xf25 >;            /* in modules/hal/stm32/dts/st/u5/stm32u585aiixq-pinctrl.dtsi:2190 */
				slew-rate = "very-high-speed"; /* in modules/hal/stm32/dts/st/u5/stm32u585aiixq-pinctrl.dtsi:2191 */
				phandle = < 0x2a >;            /* in zephyr/boards/st/b_u585i_iot02a/b_u585i_iot02a-common.dtsi:161 */
			};

			/* node '/soc/pin-controller@42020000/octospim_p2_io5_ph10' defined in modules/hal/stm32/dts/st/u5/stm32u585aiixq-pinctrl.dtsi:2194 */
			octospim_p2_io5_ph10: octospim_p2_io5_ph10 {
				pinmux = < 0xf45 >;            /* in modules/hal/stm32/dts/st/u5/stm32u585aiixq-pinctrl.dtsi:2195 */
				slew-rate = "very-high-speed"; /* in modules/hal/stm32/dts/st/u5/stm32u585aiixq-pinctrl.dtsi:2196 */
				phandle = < 0x2b >;            /* in zephyr/boards/st/b_u585i_iot02a/b_u585i_iot02a-common.dtsi:161 */
			};

			/* node '/soc/pin-controller@42020000/octospim_p2_io6_ph11' defined in modules/hal/stm32/dts/st/u5/stm32u585aiixq-pinctrl.dtsi:2199 */
			octospim_p2_io6_ph11: octospim_p2_io6_ph11 {
				pinmux = < 0xf65 >;            /* in modules/hal/stm32/dts/st/u5/stm32u585aiixq-pinctrl.dtsi:2200 */
				slew-rate = "very-high-speed"; /* in modules/hal/stm32/dts/st/u5/stm32u585aiixq-pinctrl.dtsi:2201 */
				phandle = < 0x2c >;            /* in zephyr/boards/st/b_u585i_iot02a/b_u585i_iot02a-common.dtsi:161 */
			};

			/* node '/soc/pin-controller@42020000/octospim_p2_io7_ph12' defined in modules/hal/stm32/dts/st/u5/stm32u585aiixq-pinctrl.dtsi:2204 */
			octospim_p2_io7_ph12: octospim_p2_io7_ph12 {
				pinmux = < 0xf85 >;            /* in modules/hal/stm32/dts/st/u5/stm32u585aiixq-pinctrl.dtsi:2205 */
				slew-rate = "very-high-speed"; /* in modules/hal/stm32/dts/st/u5/stm32u585aiixq-pinctrl.dtsi:2206 */
				phandle = < 0x2d >;            /* in zephyr/boards/st/b_u585i_iot02a/b_u585i_iot02a-common.dtsi:161 */
			};

			/* node '/soc/pin-controller@42020000/octospim_p1_io5_pi0' defined in modules/hal/stm32/dts/st/u5/stm32u585aiixq-pinctrl.dtsi:2214 */
			octospim_p1_io5_pi0: octospim_p1_io5_pi0 {
				pinmux = < 0x1003 >;           /* in modules/hal/stm32/dts/st/u5/stm32u585aiixq-pinctrl.dtsi:2215 */
				slew-rate = "very-high-speed"; /* in modules/hal/stm32/dts/st/u5/stm32u585aiixq-pinctrl.dtsi:2216 */
				phandle = < 0x20 >;            /* in zephyr/boards/st/b_u585i_iot02a/b_u585i_iot02a-common.dtsi:138 */
			};

			/* node '/soc/pin-controller@42020000/octospim_p2_ncs_pi5' defined in modules/hal/stm32/dts/st/u5/stm32u585aiixq-pinctrl.dtsi:2234 */
			octospim_p2_ncs_pi5: octospim_p2_ncs_pi5 {
				pinmux = < 0x10a5 >;           /* in modules/hal/stm32/dts/st/u5/stm32u585aiixq-pinctrl.dtsi:2235 */
				slew-rate = "very-high-speed"; /* in modules/hal/stm32/dts/st/u5/stm32u585aiixq-pinctrl.dtsi:2236 */
				phandle = < 0x25 >;            /* in zephyr/boards/st/b_u585i_iot02a/b_u585i_iot02a-common.dtsi:161 */
			};

			/* node '/soc/pin-controller@42020000/spi1_miso_pe14' defined in modules/hal/stm32/dts/st/u5/stm32u585aiixq-pinctrl.dtsi:2736 */
			spi1_miso_pe14: spi1_miso_pe14 {
				pinmux = < 0x9c5 >;            /* in modules/hal/stm32/dts/st/u5/stm32u585aiixq-pinctrl.dtsi:2737 */
				bias-pull-down;                /* in modules/hal/stm32/dts/st/u5/stm32u585aiixq-pinctrl.dtsi:2738 */
				slew-rate = "very-high-speed"; /* in modules/hal/stm32/dts/st/u5/stm32u585aiixq-pinctrl.dtsi:2739 */
				phandle = < 0xd >;             /* in zephyr/boards/st/b_u585i_iot02a/b_u585i_iot02a-common.dtsi:109 */
			};

			/* node '/soc/pin-controller@42020000/spi1_mosi_pe15' defined in modules/hal/stm32/dts/st/u5/stm32u585aiixq-pinctrl.dtsi:2810 */
			spi1_mosi_pe15: spi1_mosi_pe15 {
				pinmux = < 0x9e5 >;            /* in modules/hal/stm32/dts/st/u5/stm32u585aiixq-pinctrl.dtsi:2811 */
				bias-pull-down;                /* in modules/hal/stm32/dts/st/u5/stm32u585aiixq-pinctrl.dtsi:2812 */
				slew-rate = "very-high-speed"; /* in modules/hal/stm32/dts/st/u5/stm32u585aiixq-pinctrl.dtsi:2813 */
				phandle = < 0xe >;             /* in zephyr/boards/st/b_u585i_iot02a/b_u585i_iot02a-common.dtsi:109 */
			};

			/* node '/soc/pin-controller@42020000/spi1_nss_pe12' defined in modules/hal/stm32/dts/st/u5/stm32u585aiixq-pinctrl.dtsi:2890 */
			spi1_nss_pe12: spi1_nss_pe12 {
				pinmux = < 0x985 >;            /* in modules/hal/stm32/dts/st/u5/stm32u585aiixq-pinctrl.dtsi:2891 */
				bias-pull-up;                  /* in modules/hal/stm32/dts/st/u5/stm32u585aiixq-pinctrl.dtsi:2892 */
				slew-rate = "very-high-speed"; /* in modules/hal/stm32/dts/st/u5/stm32u585aiixq-pinctrl.dtsi:2893 */
				phandle = < 0xb >;             /* in zephyr/boards/st/b_u585i_iot02a/b_u585i_iot02a-common.dtsi:109 */
			};

			/* node '/soc/pin-controller@42020000/spi1_sck_pe13' defined in modules/hal/stm32/dts/st/u5/stm32u585aiixq-pinctrl.dtsi:2964 */
			spi1_sck_pe13: spi1_sck_pe13 {
				pinmux = < 0x9a5 >;            /* in modules/hal/stm32/dts/st/u5/stm32u585aiixq-pinctrl.dtsi:2965 */
				bias-pull-down;                /* in modules/hal/stm32/dts/st/u5/stm32u585aiixq-pinctrl.dtsi:2966 */
				slew-rate = "very-high-speed"; /* in modules/hal/stm32/dts/st/u5/stm32u585aiixq-pinctrl.dtsi:2967 */
				phandle = < 0xc >;             /* in zephyr/boards/st/b_u585i_iot02a/b_u585i_iot02a-common.dtsi:109 */
			};

			/* node '/soc/pin-controller@42020000/tim3_ch2_pe4' defined in modules/hal/stm32/dts/st/u5/stm32u585aiixq-pinctrl.dtsi:3250 */
			tim3_ch2_pe4: tim3_ch2_pe4 {
				pinmux = < 0x882 >; /* in modules/hal/stm32/dts/st/u5/stm32u585aiixq-pinctrl.dtsi:3251 */
				phandle = < 0x17 >; /* in zephyr/boards/st/b_u585i_iot02a/b_u585i_iot02a-common.dtsi:132 */
			};

			/* node '/soc/pin-controller@42020000/tim4_ch1_pb6' defined in modules/hal/stm32/dts/st/u5/stm32u585aiixq-pinctrl.dtsi:3262 */
			tim4_ch1_pb6: tim4_ch1_pb6 {
				pinmux = < 0x2c2 >; /* in modules/hal/stm32/dts/st/u5/stm32u585aiixq-pinctrl.dtsi:3263 */
				phandle = < 0x18 >; /* in zephyr/boards/st/b_u585i_iot02a/b_u585i_iot02a-common.dtsi:121 */
			};

			/* node '/soc/pin-controller@42020000/usart1_rx_pa10' defined in modules/hal/stm32/dts/st/u5/stm32u585aiixq-pinctrl.dtsi:3846 */
			usart1_rx_pa10: usart1_rx_pa10 {
				pinmux = < 0x147 >; /* in modules/hal/stm32/dts/st/u5/stm32u585aiixq-pinctrl.dtsi:3847 */
				phandle = < 0x6 >;  /* in zephyr/boards/st/b_u585i_iot02a/b_u585i_iot02a-common.dtsi:95 */
			};

			/* node '/soc/pin-controller@42020000/usart3_rx_pd9' defined in modules/hal/stm32/dts/st/u5/stm32u585aiixq-pinctrl.dtsi:3898 */
			usart3_rx_pd9: usart3_rx_pd9 {
				pinmux = < 0x727 >; /* in modules/hal/stm32/dts/st/u5/stm32u585aiixq-pinctrl.dtsi:3899 */
				phandle = < 0x8 >;  /* in zephyr/boards/st/b_u585i_iot02a/b_u585i_iot02a-common.dtsi:102 */
			};

			/* node '/soc/pin-controller@42020000/uart4_rx_pc11' defined in modules/hal/stm32/dts/st/u5/stm32u585aiixq-pinctrl.dtsi:3906 */
			uart4_rx_pc11: uart4_rx_pc11 {
				pinmux = < 0x568 >; /* in modules/hal/stm32/dts/st/u5/stm32u585aiixq-pinctrl.dtsi:3907 */
				phandle = < 0xa >;  /* in zephyr/boards/st/b_u585i_iot02a/b_u585i_iot02a.dts:102 */
			};

			/* node '/soc/pin-controller@42020000/usart1_tx_pa9' defined in modules/hal/stm32/dts/st/u5/stm32u585aiixq-pinctrl.dtsi:3921 */
			usart1_tx_pa9: usart1_tx_pa9 {
				pinmux = < 0x127 >; /* in modules/hal/stm32/dts/st/u5/stm32u585aiixq-pinctrl.dtsi:3922 */
				bias-pull-up;       /* in modules/hal/stm32/dts/st/u5/stm32u585aiixq-pinctrl.dtsi:3923 */
				phandle = < 0x5 >;  /* in zephyr/boards/st/b_u585i_iot02a/b_u585i_iot02a-common.dtsi:95 */
			};

			/* node '/soc/pin-controller@42020000/usart3_tx_pd8' defined in modules/hal/stm32/dts/st/u5/stm32u585aiixq-pinctrl.dtsi:3981 */
			usart3_tx_pd8: usart3_tx_pd8 {
				pinmux = < 0x707 >; /* in modules/hal/stm32/dts/st/u5/stm32u585aiixq-pinctrl.dtsi:3982 */
				bias-pull-up;       /* in modules/hal/stm32/dts/st/u5/stm32u585aiixq-pinctrl.dtsi:3983 */
				phandle = < 0x7 >;  /* in zephyr/boards/st/b_u585i_iot02a/b_u585i_iot02a-common.dtsi:102 */
			};

			/* node '/soc/pin-controller@42020000/uart4_tx_pc10' defined in modules/hal/stm32/dts/st/u5/stm32u585aiixq-pinctrl.dtsi:3991 */
			uart4_tx_pc10: uart4_tx_pc10 {
				pinmux = < 0x548 >; /* in modules/hal/stm32/dts/st/u5/stm32u585aiixq-pinctrl.dtsi:3992 */
				bias-pull-up;       /* in modules/hal/stm32/dts/st/u5/stm32u585aiixq-pinctrl.dtsi:3993 */
				phandle = < 0x9 >;  /* in zephyr/boards/st/b_u585i_iot02a/b_u585i_iot02a.dts:102 */
			};

			/* node '/soc/pin-controller@42020000/usb_otg_fs_dm_pa11' defined in modules/hal/stm32/dts/st/u5/stm32u585aiixq-pinctrl.dtsi:4025 */
			usb_otg_fs_dm_pa11: usb_otg_fs_dm_pa11 {
				pinmux = < 0x16a >; /* in modules/hal/stm32/dts/st/u5/stm32u585aiixq-pinctrl.dtsi:4026 */
				phandle = < 0x37 >; /* in zephyr/boards/st/b_u585i_iot02a/b_u585i_iot02a-common.dtsi:253 */
			};

			/* node '/soc/pin-controller@42020000/usb_otg_fs_dp_pa12' defined in modules/hal/stm32/dts/st/u5/stm32u585aiixq-pinctrl.dtsi:4029 */
			usb_otg_fs_dp_pa12: usb_otg_fs_dp_pa12 {
				pinmux = < 0x18a >; /* in modules/hal/stm32/dts/st/u5/stm32u585aiixq-pinctrl.dtsi:4030 */
				phandle = < 0x38 >; /* in zephyr/boards/st/b_u585i_iot02a/b_u585i_iot02a-common.dtsi:253 */
			};
		};

		/* node '/soc/watchdog@40003000' defined in zephyr/dts/arm/st/u5/stm32u5.dtsi:318 */
		iwdg: watchdog@40003000 {
			compatible = "st,stm32-watchdog"; /* in zephyr/dts/arm/st/u5/stm32u5.dtsi:319 */
			reg = < 0x40003000 0x400 >;       /* in zephyr/dts/arm/st/u5/stm32u5.dtsi:320 */
			interrupts = < 0x1b 0x0 >;        /* in zephyr/dts/arm/st/u5/stm32u5.dtsi:321 */
			status = "okay";                  /* in zephyr/boards/st/b_u585i_iot02a/b_u585i_iot02a-common.dtsi:291 */
		};

		/* node '/soc/watchdog@40002c00' defined in zephyr/dts/arm/st/u5/stm32u5.dtsi:325 */
		wwdg: wwdg1: watchdog@40002c00 {
			compatible = "st,stm32-window-watchdog"; /* in zephyr/dts/arm/st/u5/stm32u5.dtsi:326 */
			reg = < 0x40002c00 0x1000 >;             /* in zephyr/dts/arm/st/u5/stm32u5.dtsi:327 */
			clocks = < &rcc 0x9c 0x800 >;            /* in zephyr/dts/arm/st/u5/stm32u5.dtsi:328 */
			interrupts = < 0x0 0x0 >;                /* in zephyr/dts/arm/st/u5/stm32u5.dtsi:329 */
			status = "disabled";                     /* in zephyr/dts/arm/st/u5/stm32u5.dtsi:330 */
		};

		/* node '/soc/memory@40036400' defined in zephyr/dts/arm/st/u5/stm32u5.dtsi:333 */
		backup_sram: memory@40036400 {
			compatible = "zephyr,memory-region",
			             "st,stm32-backup-sram";  /* in zephyr/dts/arm/st/u5/stm32u5.dtsi:334 */
			reg = < 0x40036400 0x800 >;           /* in zephyr/dts/arm/st/u5/stm32u5.dtsi:335 */
			clocks = < &rcc 0x88 0x10020000 >;    /* in zephyr/dts/arm/st/u5/stm32u5.dtsi:337 */
			zephyr,memory-region = "BACKUP_SRAM"; /* in zephyr/dts/arm/st/u5/stm32u5.dtsi:338 */
			status = "disabled";                  /* in zephyr/dts/arm/st/u5/stm32u5.dtsi:339 */
		};

		/* node '/soc/serial@40013800' defined in zephyr/dts/arm/st/u5/stm32u5.dtsi:342 */
		usart1: serial@40013800 {
			compatible = "st,stm32-usart",
			             "st,stm32-uart";                   /* in zephyr/dts/arm/st/u5/stm32u5.dtsi:343 */
			reg = < 0x40013800 0x400 >;                     /* in zephyr/dts/arm/st/u5/stm32u5.dtsi:344 */
			clocks = < &rcc 0xa4 0x4000 >;                  /* in zephyr/dts/arm/st/u5/stm32u5.dtsi:345 */
			resets = < &rctl 0xf8e >;                       /* in zephyr/dts/arm/st/u5/stm32u5.dtsi:346 */
			interrupts = < 0x3d 0x0 >;                      /* in zephyr/dts/arm/st/u5/stm32u5.dtsi:347 */
			pinctrl-0 = < &usart1_tx_pa9 &usart1_rx_pa10 >; /* in zephyr/boards/st/b_u585i_iot02a/b_u585i_iot02a-common.dtsi:95 */
			pinctrl-names = "default";                      /* in zephyr/boards/st/b_u585i_iot02a/b_u585i_iot02a-common.dtsi:96 */
			current-speed = < 0x1c200 >;                    /* in zephyr/boards/st/b_u585i_iot02a/b_u585i_iot02a-common.dtsi:97 */
			status = "okay";                                /* in zephyr/boards/st/b_u585i_iot02a/b_u585i_iot02a-common.dtsi:98 */
		};

		/* node '/soc/serial@40004800' defined in zephyr/dts/arm/st/u5/stm32u5.dtsi:351 */
		usart3: arduino_serial: serial@40004800 {
			compatible = "st,stm32-usart",
			             "st,stm32-uart";                  /* in zephyr/dts/arm/st/u5/stm32u5.dtsi:352 */
			reg = < 0x40004800 0x400 >;                    /* in zephyr/dts/arm/st/u5/stm32u5.dtsi:353 */
			clocks = < &rcc 0x9c 0x40000 >;                /* in zephyr/dts/arm/st/u5/stm32u5.dtsi:354 */
			resets = < &rctl 0xe92 >;                      /* in zephyr/dts/arm/st/u5/stm32u5.dtsi:355 */
			interrupts = < 0x3f 0x0 >;                     /* in zephyr/dts/arm/st/u5/stm32u5.dtsi:356 */
			pinctrl-0 = < &usart3_tx_pd8 &usart3_rx_pd9 >; /* in zephyr/boards/st/b_u585i_iot02a/b_u585i_iot02a-common.dtsi:102 */
			pinctrl-names = "default";                     /* in zephyr/boards/st/b_u585i_iot02a/b_u585i_iot02a-common.dtsi:103 */
			current-speed = < 0x1c200 >;                   /* in zephyr/boards/st/b_u585i_iot02a/b_u585i_iot02a-common.dtsi:104 */
			status = "okay";                               /* in zephyr/boards/st/b_u585i_iot02a/b_u585i_iot02a-common.dtsi:105 */
		};

		/* node '/soc/serial@40004c00' defined in zephyr/dts/arm/st/u5/stm32u5.dtsi:360 */
		uart4: serial@40004c00 {
			compatible = "st,stm32-uart";                  /* in zephyr/dts/arm/st/u5/stm32u5.dtsi:361 */
			reg = < 0x40004c00 0x400 >;                    /* in zephyr/dts/arm/st/u5/stm32u5.dtsi:362 */
			clocks = < &rcc 0x9c 0x80000 >;                /* in zephyr/dts/arm/st/u5/stm32u5.dtsi:363 */
			resets = < &rctl 0xe93 >;                      /* in zephyr/dts/arm/st/u5/stm32u5.dtsi:364 */
			interrupts = < 0x40 0x0 >;                     /* in zephyr/dts/arm/st/u5/stm32u5.dtsi:365 */
			pinctrl-0 = < &uart4_tx_pc10 &uart4_rx_pc11 >; /* in zephyr/boards/st/b_u585i_iot02a/b_u585i_iot02a.dts:102 */
			pinctrl-names = "default";                     /* in zephyr/boards/st/b_u585i_iot02a/b_u585i_iot02a.dts:103 */
			current-speed = < 0x186a0 >;                   /* in zephyr/boards/st/b_u585i_iot02a/b_u585i_iot02a.dts:104 */
			status = "okay";                               /* in zephyr/boards/st/b_u585i_iot02a/b_u585i_iot02a.dts:105 */

			/* node '/soc/serial@40004c00/bt_hci_uart' defined in zephyr/boards/st/b_u585i_iot02a/b_u585i_iot02a.dts:107 */
			bt_hci_uart: bt_hci_uart {
				compatible = "zephyr,bt-hci-uart"; /* in zephyr/boards/st/b_u585i_iot02a/b_u585i_iot02a.dts:108 */
				status = "okay";                   /* in zephyr/boards/st/b_u585i_iot02a/b_u585i_iot02a.dts:109 */
			};
		};

		/* node '/soc/serial@40005000' defined in zephyr/dts/arm/st/u5/stm32u5.dtsi:369 */
		uart5: serial@40005000 {
			compatible = "st,stm32-uart";    /* in zephyr/dts/arm/st/u5/stm32u5.dtsi:370 */
			reg = < 0x40005000 0x400 >;      /* in zephyr/dts/arm/st/u5/stm32u5.dtsi:371 */
			clocks = < &rcc 0x9c 0x100000 >; /* in zephyr/dts/arm/st/u5/stm32u5.dtsi:372 */
			resets = < &rctl 0xe94 >;        /* in zephyr/dts/arm/st/u5/stm32u5.dtsi:373 */
			interrupts = < 0x41 0x0 >;       /* in zephyr/dts/arm/st/u5/stm32u5.dtsi:374 */
			status = "disabled";             /* in zephyr/dts/arm/st/u5/stm32u5.dtsi:375 */
		};

		/* node '/soc/serial@46002400' defined in zephyr/dts/arm/st/u5/stm32u5.dtsi:378 */
		lpuart1: serial@46002400 {
			compatible = "st,stm32-lpuart",
			             "st,stm32-uart";   /* in zephyr/dts/arm/st/u5/stm32u5.dtsi:379 */
			reg = < 0x46002400 0x400 >;     /* in zephyr/dts/arm/st/u5/stm32u5.dtsi:380 */
			clocks = < &rcc 0xa8 0x40 >;    /* in zephyr/dts/arm/st/u5/stm32u5.dtsi:381 */
			resets = < &rctl 0x1006 >;      /* in zephyr/dts/arm/st/u5/stm32u5.dtsi:382 */
			interrupts = < 0x42 0x0 >;      /* in zephyr/dts/arm/st/u5/stm32u5.dtsi:383 */
			status = "disabled";            /* in zephyr/dts/arm/st/u5/stm32u5.dtsi:384 */
		};

		/* node '/soc/spi@40013000' defined in zephyr/dts/arm/st/u5/stm32u5.dtsi:387 */
		spi1: arduino_spi: spi@40013000 {
			compatible = "st,stm32h7-spi",
			             "st,stm32-spi-fifo",
			             "st,stm32-spi";                                                   /* in zephyr/dts/arm/st/u5/stm32u5.dtsi:388 */
			#address-cells = < 0x1 >;                                                      /* in zephyr/dts/arm/st/u5/stm32u5.dtsi:389 */
			#size-cells = < 0x0 >;                                                         /* in zephyr/dts/arm/st/u5/stm32u5.dtsi:390 */
			reg = < 0x40013000 0x400 >;                                                    /* in zephyr/dts/arm/st/u5/stm32u5.dtsi:391 */
			interrupts = < 0x3b 0x0 >;                                                     /* in zephyr/dts/arm/st/u5/stm32u5.dtsi:392 */
			clocks = < &rcc 0xa4 0x1000 >;                                                 /* in zephyr/dts/arm/st/u5/stm32u5.dtsi:393 */
			st,spi-data-width = "full-4-to-32-bit";                                        /* in zephyr/dts/arm/st/u5/stm32u5.dtsi:394 */
			fifo-size = < 0x10 >;                                                          /* in zephyr/dts/arm/st/u5/stm32u5.dtsi:395 */
			fifo-max-transfer-size = < 0xffff >;                                           /* in zephyr/dts/arm/st/u5/stm32u5.dtsi:396 */
			pinctrl-0 = < &spi1_nss_pe12 &spi1_sck_pe13 &spi1_miso_pe14 &spi1_mosi_pe15 >; /* in zephyr/boards/st/b_u585i_iot02a/b_u585i_iot02a-common.dtsi:109 */
			pinctrl-names = "default";                                                     /* in zephyr/boards/st/b_u585i_iot02a/b_u585i_iot02a-common.dtsi:111 */
			status = "okay";                                                               /* in zephyr/boards/st/b_u585i_iot02a/b_u585i_iot02a-common.dtsi:112 */
		};

		/* node '/soc/spi@40003800' defined in zephyr/dts/arm/st/u5/stm32u5.dtsi:400 */
		spi2: spi@40003800 {
			compatible = "st,stm32h7-spi",
			             "st,stm32-spi-fifo",
			             "st,stm32-spi";            /* in zephyr/dts/arm/st/u5/stm32u5.dtsi:401 */
			#address-cells = < 0x1 >;               /* in zephyr/dts/arm/st/u5/stm32u5.dtsi:402 */
			#size-cells = < 0x0 >;                  /* in zephyr/dts/arm/st/u5/stm32u5.dtsi:403 */
			reg = < 0x40003800 0x400 >;             /* in zephyr/dts/arm/st/u5/stm32u5.dtsi:404 */
			interrupts = < 0x3c 0x0 >;              /* in zephyr/dts/arm/st/u5/stm32u5.dtsi:405 */
			clocks = < &rcc 0x9c 0x4000 >;          /* in zephyr/dts/arm/st/u5/stm32u5.dtsi:406 */
			st,spi-data-width = "full-4-to-32-bit"; /* in zephyr/dts/arm/st/u5/stm32u5.dtsi:407 */
			fifo-size = < 0x10 >;                   /* in zephyr/dts/arm/st/u5/stm32u5.dtsi:408 */
			fifo-max-transfer-size = < 0xffff >;    /* in zephyr/dts/arm/st/u5/stm32u5.dtsi:409 */
			status = "disabled";                    /* in zephyr/dts/arm/st/u5/stm32u5.dtsi:410 */
		};

		/* node '/soc/spi@46002000' defined in zephyr/dts/arm/st/u5/stm32u5.dtsi:413 */
		spi3: spi@46002000 {
			compatible = "st,stm32h7-spi",
			             "st,stm32-spi-fifo",
			             "st,stm32-spi";            /* in zephyr/dts/arm/st/u5/stm32u5.dtsi:414 */
			#address-cells = < 0x1 >;               /* in zephyr/dts/arm/st/u5/stm32u5.dtsi:415 */
			#size-cells = < 0x0 >;                  /* in zephyr/dts/arm/st/u5/stm32u5.dtsi:416 */
			reg = < 0x46002000 0x400 >;             /* in zephyr/dts/arm/st/u5/stm32u5.dtsi:417 */
			interrupts = < 0x63 0x0 >;              /* in zephyr/dts/arm/st/u5/stm32u5.dtsi:418 */
			clocks = < &rcc 0xa8 0x20 >;            /* in zephyr/dts/arm/st/u5/stm32u5.dtsi:419 */
			st,spi-data-width = "limited-8-16-bit"; /* in zephyr/dts/arm/st/u5/stm32u5.dtsi:420 */
			fifo-size = < 0x8 >;                    /* in zephyr/dts/arm/st/u5/stm32u5.dtsi:421 */
			fifo-max-transfer-size = < 0x3ff >;     /* in zephyr/dts/arm/st/u5/stm32u5.dtsi:422 */
			status = "disabled";                    /* in zephyr/dts/arm/st/u5/stm32u5.dtsi:423 */
		};

		/* node '/soc/i2c@40005400' defined in zephyr/dts/arm/st/u5/stm32u5.dtsi:426 */
		i2c1: arduino_i2c: i2c@40005400 {
			compatible = "st,stm32-i2c-v2";              /* in zephyr/dts/arm/st/u5/stm32u5.dtsi:427 */
			#address-cells = < 0x1 >;                    /* in zephyr/dts/arm/st/u5/stm32u5.dtsi:429 */
			#size-cells = < 0x0 >;                       /* in zephyr/dts/arm/st/u5/stm32u5.dtsi:430 */
			reg = < 0x40005400 0x400 >;                  /* in zephyr/dts/arm/st/u5/stm32u5.dtsi:431 */
			clocks = < &rcc 0x9c 0x200000 >;             /* in zephyr/dts/arm/st/u5/stm32u5.dtsi:432 */
			interrupts = < 0x37 0x0 >,
			             < 0x38 0x0 >;                   /* in zephyr/dts/arm/st/u5/stm32u5.dtsi:433 */
			interrupt-names = "event",
			                  "error";                   /* in zephyr/dts/arm/st/u5/stm32u5.dtsi:434 */
			pinctrl-0 = < &i2c1_scl_pb8 &i2c1_sda_pb9 >; /* in zephyr/boards/st/b_u585i_iot02a/b_u585i_iot02a-common.dtsi:196 */
			pinctrl-names = "default";                   /* in zephyr/boards/st/b_u585i_iot02a/b_u585i_iot02a-common.dtsi:197 */
			status = "okay";                             /* in zephyr/boards/st/b_u585i_iot02a/b_u585i_iot02a-common.dtsi:198 */
			clock-frequency = < 0x61a80 >;               /* in zephyr/boards/st/b_u585i_iot02a/b_u585i_iot02a-common.dtsi:199 */
			phandle = < 0x4c >;                          /* in zephyr/dts/arm/st/u5/stm32u5.dtsi:1118 */
		};

		/* node '/soc/i2c@40005800' defined in zephyr/dts/arm/st/u5/stm32u5.dtsi:438 */
		i2c2: i2c@40005800 {
			compatible = "st,stm32-i2c-v2";              /* in zephyr/dts/arm/st/u5/stm32u5.dtsi:439 */
			#address-cells = < 0x1 >;                    /* in zephyr/dts/arm/st/u5/stm32u5.dtsi:441 */
			#size-cells = < 0x0 >;                       /* in zephyr/dts/arm/st/u5/stm32u5.dtsi:442 */
			reg = < 0x40005800 0x400 >;                  /* in zephyr/dts/arm/st/u5/stm32u5.dtsi:443 */
			clocks = < &rcc 0x9c 0x400000 >;             /* in zephyr/dts/arm/st/u5/stm32u5.dtsi:444 */
			interrupts = < 0x39 0x0 >,
			             < 0x3a 0x0 >;                   /* in zephyr/dts/arm/st/u5/stm32u5.dtsi:445 */
			interrupt-names = "event",
			                  "error";                   /* in zephyr/dts/arm/st/u5/stm32u5.dtsi:446 */
			pinctrl-0 = < &i2c2_scl_ph4 &i2c2_sda_ph5 >; /* in zephyr/boards/st/b_u585i_iot02a/b_u585i_iot02a-common.dtsi:203 */
			pinctrl-names = "default";                   /* in zephyr/boards/st/b_u585i_iot02a/b_u585i_iot02a-common.dtsi:204 */
			status = "okay";                             /* in zephyr/boards/st/b_u585i_iot02a/b_u585i_iot02a-common.dtsi:205 */
			clock-frequency = < 0x61a80 >;               /* in zephyr/boards/st/b_u585i_iot02a/b_u585i_iot02a-common.dtsi:206 */
			phandle = < 0x4d >;                          /* in zephyr/dts/arm/st/u5/stm32u5.dtsi:1126 */

			/* node '/soc/i2c@40005800/veml6030@10' defined in zephyr/boards/st/b_u585i_iot02a/b_u585i_iot02a-common.dtsi:208 */
			veml6030@10 {
				compatible = "vishay,veml7700"; /* in zephyr/boards/st/b_u585i_iot02a/b_u585i_iot02a-common.dtsi:209 */
				reg = < 0x10 >;                 /* in zephyr/boards/st/b_u585i_iot02a/b_u585i_iot02a-common.dtsi:210 */
				status = "okay";                /* in zephyr/boards/st/b_u585i_iot02a/b_u585i_iot02a-common.dtsi:211 */
			};

			/* node '/soc/i2c@40005800/iis2mdc@1e' defined in zephyr/boards/st/b_u585i_iot02a/b_u585i_iot02a-common.dtsi:214 */
			iis2mdc@1e {
				compatible = "st,iis2mdc";       /* in zephyr/boards/st/b_u585i_iot02a/b_u585i_iot02a-common.dtsi:215 */
				reg = < 0x1e >;                  /* in zephyr/boards/st/b_u585i_iot02a/b_u585i_iot02a-common.dtsi:216 */
				drdy-gpios = < &gpiod 0xa 0x0 >; /* in zephyr/boards/st/b_u585i_iot02a/b_u585i_iot02a-common.dtsi:217 */
			};

			/* node '/soc/i2c@40005800/ism330dhcx@6b' defined in zephyr/boards/st/b_u585i_iot02a/b_u585i_iot02a-common.dtsi:220 */
			ism330dhcx@6b {
				compatible = "st,ism330dhcx";    /* in zephyr/boards/st/b_u585i_iot02a/b_u585i_iot02a-common.dtsi:221 */
				reg = < 0x6b >;                  /* in zephyr/boards/st/b_u585i_iot02a/b_u585i_iot02a-common.dtsi:222 */
				drdy-gpios = < &gpioe 0xb 0x0 >; /* in zephyr/boards/st/b_u585i_iot02a/b_u585i_iot02a-common.dtsi:223 */
			};

			/* node '/soc/i2c@40005800/lps22hh@5d' defined in zephyr/boards/st/b_u585i_iot02a/b_u585i_iot02a-common.dtsi:226 */
			lps22hh@5d {
				compatible = "st,lps22hh";       /* in zephyr/boards/st/b_u585i_iot02a/b_u585i_iot02a-common.dtsi:227 */
				reg = < 0x5d >;                  /* in zephyr/boards/st/b_u585i_iot02a/b_u585i_iot02a-common.dtsi:228 */
				drdy-gpios = < &gpiog 0x2 0x0 >; /* in zephyr/boards/st/b_u585i_iot02a/b_u585i_iot02a-common.dtsi:229 */
			};

			/* node '/soc/i2c@40005800/eeprom@56' defined in zephyr/boards/st/b_u585i_iot02a/b_u585i_iot02a-common.dtsi:232 */
			eeprom0: eeprom@56 {
				compatible = "atmel,at24"; /* in zephyr/boards/st/b_u585i_iot02a/b_u585i_iot02a-common.dtsi:233 */
				reg = < 0x56 >;            /* in zephyr/boards/st/b_u585i_iot02a/b_u585i_iot02a-common.dtsi:234 */
				status = "okay";           /* in zephyr/boards/st/b_u585i_iot02a/b_u585i_iot02a-common.dtsi:235 */
				size = < 0x8000 >;         /* in zephyr/boards/st/b_u585i_iot02a/b_u585i_iot02a-common.dtsi:236 */
				pagesize = < 0x40 >;       /* in zephyr/boards/st/b_u585i_iot02a/b_u585i_iot02a-common.dtsi:237 */
				address-width = < 0x10 >;  /* in zephyr/boards/st/b_u585i_iot02a/b_u585i_iot02a-common.dtsi:238 */
				timeout = < 0x5 >;         /* in zephyr/boards/st/b_u585i_iot02a/b_u585i_iot02a-common.dtsi:239 */
			};

			/* node '/soc/i2c@40005800/hts221@5f' defined in zephyr/boards/st/b_u585i_iot02a/b_u585i_iot02a-common.dtsi:242 */
			hts221@5f {
				compatible = "st,hts221"; /* in zephyr/boards/st/b_u585i_iot02a/b_u585i_iot02a-common.dtsi:243 */
				reg = < 0x5f >;           /* in zephyr/boards/st/b_u585i_iot02a/b_u585i_iot02a-common.dtsi:244 */
			};
		};

		/* node '/soc/i2c@46002800' defined in zephyr/dts/arm/st/u5/stm32u5.dtsi:450 */
		i2c3: i2c@46002800 {
			compatible = "st,stm32-i2c-v2"; /* in zephyr/dts/arm/st/u5/stm32u5.dtsi:451 */
			clock-frequency = < 0x186a0 >;  /* in zephyr/dts/arm/st/u5/stm32u5.dtsi:452 */
			#address-cells = < 0x1 >;       /* in zephyr/dts/arm/st/u5/stm32u5.dtsi:453 */
			#size-cells = < 0x0 >;          /* in zephyr/dts/arm/st/u5/stm32u5.dtsi:454 */
			reg = < 0x46002800 0x400 >;     /* in zephyr/dts/arm/st/u5/stm32u5.dtsi:455 */
			clocks = < &rcc 0xa8 0x80 >;    /* in zephyr/dts/arm/st/u5/stm32u5.dtsi:456 */
			interrupts = < 0x58 0x0 >,
			             < 0x59 0x0 >;      /* in zephyr/dts/arm/st/u5/stm32u5.dtsi:457 */
			interrupt-names = "event",
			                  "error";      /* in zephyr/dts/arm/st/u5/stm32u5.dtsi:458 */
			status = "disabled";            /* in zephyr/dts/arm/st/u5/stm32u5.dtsi:459 */
			phandle = < 0x4e >;             /* in zephyr/dts/arm/st/u5/stm32u5.dtsi:1134 */
		};

		/* node '/soc/i2c@40008400' defined in zephyr/dts/arm/st/u5/stm32u5.dtsi:462 */
		i2c4: i2c@40008400 {
			compatible = "st,stm32-i2c-v2"; /* in zephyr/dts/arm/st/u5/stm32u5.dtsi:463 */
			clock-frequency = < 0x186a0 >;  /* in zephyr/dts/arm/st/u5/stm32u5.dtsi:464 */
			#address-cells = < 0x1 >;       /* in zephyr/dts/arm/st/u5/stm32u5.dtsi:465 */
			#size-cells = < 0x0 >;          /* in zephyr/dts/arm/st/u5/stm32u5.dtsi:466 */
			reg = < 0x40008400 0x400 >;     /* in zephyr/dts/arm/st/u5/stm32u5.dtsi:467 */
			clocks = < &rcc 0xa0 0x2 >;     /* in zephyr/dts/arm/st/u5/stm32u5.dtsi:468 */
			interrupts = < 0x65 0x0 >,
			             < 0x64 0x0 >;      /* in zephyr/dts/arm/st/u5/stm32u5.dtsi:469 */
			interrupt-names = "event",
			                  "error";      /* in zephyr/dts/arm/st/u5/stm32u5.dtsi:470 */
			status = "disabled";            /* in zephyr/dts/arm/st/u5/stm32u5.dtsi:471 */
			phandle = < 0x4f >;             /* in zephyr/dts/arm/st/u5/stm32u5.dtsi:1142 */
		};

		/* node '/soc/timers@46004400' defined in zephyr/dts/arm/st/u5/stm32u5.dtsi:474 */
		lptim1: stm32_lp_tick_source: timers@46004400 {
			compatible = "st,stm32-lptim";   /* in zephyr/dts/arm/st/u5/stm32u5.dtsi:475 */
			#address-cells = < 0x1 >;        /* in zephyr/dts/arm/st/u5/stm32u5.dtsi:476 */
			#size-cells = < 0x0 >;           /* in zephyr/dts/arm/st/u5/stm32u5.dtsi:477 */
			reg = < 0x46004400 0x400 >;      /* in zephyr/dts/arm/st/u5/stm32u5.dtsi:478 */
			resets = < &rctl 0x100b >;       /* in zephyr/dts/arm/st/u5/stm32u5.dtsi:480 */
			interrupts = < 0x43 0x0 >;       /* in zephyr/dts/arm/st/u5/stm32u5.dtsi:481 */
			interrupt-names = "wakeup";      /* in zephyr/dts/arm/st/u5/stm32u5.dtsi:482 */
			clocks = < &rcc 0xa8 0x800 >,
			         < &rcc 0x2 0x32a00e8 >; /* in zephyr/boards/st/b_u585i_iot02a/b_u585i_iot02a-common.dtsi:89 */
			status = "okay";                 /* in zephyr/boards/st/b_u585i_iot02a/b_u585i_iot02a-common.dtsi:91 */
		};

		/* node '/soc/timers@40009400' defined in zephyr/dts/arm/st/u5/stm32u5.dtsi:486 */
		lptim2: timers@40009400 {
			compatible = "st,stm32-lptim"; /* in zephyr/dts/arm/st/u5/stm32u5.dtsi:487 */
			#address-cells = < 0x1 >;      /* in zephyr/dts/arm/st/u5/stm32u5.dtsi:488 */
			#size-cells = < 0x0 >;         /* in zephyr/dts/arm/st/u5/stm32u5.dtsi:489 */
			reg = < 0x40009400 0x400 >;    /* in zephyr/dts/arm/st/u5/stm32u5.dtsi:490 */
			clocks = < &rcc 0xa0 0x20 >;   /* in zephyr/dts/arm/st/u5/stm32u5.dtsi:491 */
			resets = < &rctl 0xf05 >;      /* in zephyr/dts/arm/st/u5/stm32u5.dtsi:492 */
			interrupts = < 0x44 0x0 >;     /* in zephyr/dts/arm/st/u5/stm32u5.dtsi:493 */
			interrupt-names = "global";    /* in zephyr/dts/arm/st/u5/stm32u5.dtsi:494 */
			status = "disabled";           /* in zephyr/dts/arm/st/u5/stm32u5.dtsi:495 */
		};

		/* node '/soc/timers@46004800' defined in zephyr/dts/arm/st/u5/stm32u5.dtsi:498 */
		lptim3: timers@46004800 {
			compatible = "st,stm32-lptim"; /* in zephyr/dts/arm/st/u5/stm32u5.dtsi:499 */
			#address-cells = < 0x1 >;      /* in zephyr/dts/arm/st/u5/stm32u5.dtsi:500 */
			#size-cells = < 0x0 >;         /* in zephyr/dts/arm/st/u5/stm32u5.dtsi:501 */
			reg = < 0x46004800 0x400 >;    /* in zephyr/dts/arm/st/u5/stm32u5.dtsi:502 */
			clocks = < &rcc 0xa8 0x1000 >; /* in zephyr/dts/arm/st/u5/stm32u5.dtsi:503 */
			resets = < &rctl 0x100c >;     /* in zephyr/dts/arm/st/u5/stm32u5.dtsi:504 */
			interrupts = < 0x62 0x0 >;     /* in zephyr/dts/arm/st/u5/stm32u5.dtsi:505 */
			interrupt-names = "global";    /* in zephyr/dts/arm/st/u5/stm32u5.dtsi:506 */
			status = "disabled";           /* in zephyr/dts/arm/st/u5/stm32u5.dtsi:507 */
		};

		/* node '/soc/timers@46004c00' defined in zephyr/dts/arm/st/u5/stm32u5.dtsi:510 */
		lptim4: timers@46004c00 {
			compatible = "st,stm32-lptim"; /* in zephyr/dts/arm/st/u5/stm32u5.dtsi:511 */
			#address-cells = < 0x1 >;      /* in zephyr/dts/arm/st/u5/stm32u5.dtsi:512 */
			#size-cells = < 0x0 >;         /* in zephyr/dts/arm/st/u5/stm32u5.dtsi:513 */
			reg = < 0x46004c00 0x400 >;    /* in zephyr/dts/arm/st/u5/stm32u5.dtsi:514 */
			clocks = < &rcc 0xa8 0x2000 >; /* in zephyr/dts/arm/st/u5/stm32u5.dtsi:515 */
			resets = < &rctl 0x100d >;     /* in zephyr/dts/arm/st/u5/stm32u5.dtsi:516 */
			interrupts = < 0x6e 0x0 >;     /* in zephyr/dts/arm/st/u5/stm32u5.dtsi:517 */
			interrupt-names = "global";    /* in zephyr/dts/arm/st/u5/stm32u5.dtsi:518 */
			status = "disabled";           /* in zephyr/dts/arm/st/u5/stm32u5.dtsi:519 */
		};

		/* node '/soc/rtc@46007800' defined in zephyr/dts/arm/st/u5/stm32u5.dtsi:522 */
		rtc: rtc@46007800 {
			compatible = "st,stm32-rtc";     /* in zephyr/dts/arm/st/u5/stm32u5.dtsi:523 */
			reg = < 0x46007800 0x400 >;      /* in zephyr/dts/arm/st/u5/stm32u5.dtsi:524 */
			interrupts = < 0x2 0x0 >;        /* in zephyr/dts/arm/st/u5/stm32u5.dtsi:525 */
			prescaler = < 0x8000 >;          /* in zephyr/dts/arm/st/u5/stm32u5.dtsi:527 */
			alarms-count = < 0x2 >;          /* in zephyr/dts/arm/st/u5/stm32u5.dtsi:528 */
			clocks = < &rcc 0xa8 0x200000 >,
			         < &rcc 0x2 0x12800f0 >; /* in zephyr/boards/st/b_u585i_iot02a/b_u585i_iot02a-common.dtsi:285 */
			status = "okay";                 /* in zephyr/boards/st/b_u585i_iot02a/b_u585i_iot02a-common.dtsi:287 */
		};

		/* node '/soc/sai1@40015404' defined in zephyr/dts/arm/st/u5/stm32u5.dtsi:532 */
		sai1_a: sai1@40015404 {
			compatible = "st,stm32-sai";         /* in zephyr/dts/arm/st/u5/stm32u5.dtsi:533 */
			#address-cells = < 0x1 >;            /* in zephyr/dts/arm/st/u5/stm32u5.dtsi:534 */
			#size-cells = < 0x0 >;               /* in zephyr/dts/arm/st/u5/stm32u5.dtsi:535 */
			reg = < 0x40015404 0x20 >;           /* in zephyr/dts/arm/st/u5/stm32u5.dtsi:536 */
			clocks = < &rcc 0xa4 0x200000 >,
			         < &rcc 0x12 0x4500e4 >;     /* in zephyr/dts/arm/st/u5/stm32u5.dtsi:537 */
			dmas = < &gpdma1 0x1 0x24 0x22800 >; /* in zephyr/dts/arm/st/u5/stm32u5.dtsi:539 */
			status = "disabled";                 /* in zephyr/dts/arm/st/u5/stm32u5.dtsi:541 */
		};

		/* node '/soc/sai1@40015424' defined in zephyr/dts/arm/st/u5/stm32u5.dtsi:544 */
		sai1_b: sai1@40015424 {
			compatible = "st,stm32-sai";         /* in zephyr/dts/arm/st/u5/stm32u5.dtsi:545 */
			#address-cells = < 0x1 >;            /* in zephyr/dts/arm/st/u5/stm32u5.dtsi:546 */
			#size-cells = < 0x0 >;               /* in zephyr/dts/arm/st/u5/stm32u5.dtsi:547 */
			reg = < 0x40015424 0x20 >;           /* in zephyr/dts/arm/st/u5/stm32u5.dtsi:548 */
			clocks = < &rcc 0xa4 0x200000 >,
			         < &rcc 0x12 0x4500e4 >;     /* in zephyr/dts/arm/st/u5/stm32u5.dtsi:549 */
			dmas = < &gpdma1 0x0 0x25 0x22800 >; /* in zephyr/dts/arm/st/u5/stm32u5.dtsi:551 */
			status = "disabled";                 /* in zephyr/dts/arm/st/u5/stm32u5.dtsi:553 */
		};

		/* node '/soc/timers@40012c00' defined in zephyr/dts/arm/st/u5/stm32u5.dtsi:556 */
		timers1: timers@40012c00 {
			compatible = "st,stm32-timers"; /* in zephyr/dts/arm/st/u5/stm32u5.dtsi:557 */
			reg = < 0x40012c00 0x400 >;     /* in zephyr/dts/arm/st/u5/stm32u5.dtsi:558 */
			clocks = < &rcc 0xa4 0x800 >,
			         < &rcc 0xe 0xff >;     /* in zephyr/dts/arm/st/u5/stm32u5.dtsi:559 */
			resets = < &rctl 0xf8b >;       /* in zephyr/dts/arm/st/u5/stm32u5.dtsi:561 */
			interrupts = < 0x29 0x0 >,
			             < 0x2a 0x0 >,
			             < 0x2b 0x0 >,
			             < 0x2c 0x0 >;      /* in zephyr/dts/arm/st/u5/stm32u5.dtsi:562 */
			interrupt-names = "brk",
			                  "up",
			                  "trgcom",
			                  "cc";         /* in zephyr/dts/arm/st/u5/stm32u5.dtsi:563 */
			status = "disabled";            /* in zephyr/dts/arm/st/u5/stm32u5.dtsi:564 */

			/* node '/soc/timers@40012c00/pwm' defined in zephyr/dts/arm/st/u5/stm32u5.dtsi:566 */
			pwm {
				compatible = "st,stm32-pwm"; /* in zephyr/dts/arm/st/u5/stm32u5.dtsi:567 */
				status = "disabled";         /* in zephyr/dts/arm/st/u5/stm32u5.dtsi:568 */
				#pwm-cells = < 0x3 >;        /* in zephyr/dts/arm/st/u5/stm32u5.dtsi:569 */
			};

			/* node '/soc/timers@40012c00/counter' defined in zephyr/dts/arm/st/u5/stm32u5.dtsi:572 */
			counter {
				compatible = "st,stm32-counter"; /* in zephyr/dts/arm/st/u5/stm32u5.dtsi:573 */
				status = "disabled";             /* in zephyr/dts/arm/st/u5/stm32u5.dtsi:574 */
			};

			/* node '/soc/timers@40012c00/qdec' defined in zephyr/dts/arm/st/u5/stm32u5.dtsi:577 */
			qdec {
				compatible = "st,stm32-qdec";    /* in zephyr/dts/arm/st/u5/stm32u5.dtsi:578 */
				st,input-filter-level = < 0x0 >; /* in zephyr/dts/arm/st/u5/stm32u5.dtsi:579 */
				status = "disabled";             /* in zephyr/dts/arm/st/u5/stm32u5.dtsi:580 */
			};
		};

		/* node '/soc/timers@40000000' defined in zephyr/dts/arm/st/u5/stm32u5.dtsi:584 */
		timers2: timers@40000000 {
			compatible = "st,stm32-timers"; /* in zephyr/dts/arm/st/u5/stm32u5.dtsi:585 */
			reg = < 0x40000000 0x400 >;     /* in zephyr/dts/arm/st/u5/stm32u5.dtsi:586 */
			clocks = < &rcc 0x9c 0x1 >,
			         < &rcc 0xd 0xff >;     /* in zephyr/dts/arm/st/u5/stm32u5.dtsi:587 */
			resets = < &rctl 0xe80 >;       /* in zephyr/dts/arm/st/u5/stm32u5.dtsi:589 */
			interrupts = < 0x2d 0x0 >;      /* in zephyr/dts/arm/st/u5/stm32u5.dtsi:590 */
			interrupt-names = "global";     /* in zephyr/dts/arm/st/u5/stm32u5.dtsi:591 */
			status = "disabled";            /* in zephyr/dts/arm/st/u5/stm32u5.dtsi:592 */

			/* node '/soc/timers@40000000/pwm' defined in zephyr/dts/arm/st/u5/stm32u5.dtsi:594 */
			pwm {
				compatible = "st,stm32-pwm"; /* in zephyr/dts/arm/st/u5/stm32u5.dtsi:595 */
				status = "disabled";         /* in zephyr/dts/arm/st/u5/stm32u5.dtsi:596 */
				#pwm-cells = < 0x3 >;        /* in zephyr/dts/arm/st/u5/stm32u5.dtsi:597 */
			};

			/* node '/soc/timers@40000000/counter' defined in zephyr/dts/arm/st/u5/stm32u5.dtsi:600 */
			counter {
				compatible = "st,stm32-counter"; /* in zephyr/dts/arm/st/u5/stm32u5.dtsi:601 */
				status = "disabled";             /* in zephyr/dts/arm/st/u5/stm32u5.dtsi:602 */
			};

			/* node '/soc/timers@40000000/qdec' defined in zephyr/dts/arm/st/u5/stm32u5.dtsi:605 */
			qdec {
				compatible = "st,stm32-qdec";    /* in zephyr/dts/arm/st/u5/stm32u5.dtsi:606 */
				st,input-filter-level = < 0x0 >; /* in zephyr/dts/arm/st/u5/stm32u5.dtsi:607 */
				status = "disabled";             /* in zephyr/dts/arm/st/u5/stm32u5.dtsi:608 */
			};
		};

		/* node '/soc/timers@40000400' defined in zephyr/dts/arm/st/u5/stm32u5.dtsi:612 */
		timers3: timers@40000400 {
			compatible = "st,stm32-timers"; /* in zephyr/dts/arm/st/u5/stm32u5.dtsi:613 */
			reg = < 0x40000400 0x400 >;     /* in zephyr/dts/arm/st/u5/stm32u5.dtsi:614 */
			clocks = < &rcc 0x9c 0x2 >,
			         < &rcc 0xd 0xff >;     /* in zephyr/dts/arm/st/u5/stm32u5.dtsi:615 */
			resets = < &rctl 0xe81 >;       /* in zephyr/dts/arm/st/u5/stm32u5.dtsi:617 */
			interrupts = < 0x2e 0x0 >;      /* in zephyr/dts/arm/st/u5/stm32u5.dtsi:618 */
			interrupt-names = "global";     /* in zephyr/dts/arm/st/u5/stm32u5.dtsi:619 */
			status = "okay";                /* in zephyr/boards/st/b_u585i_iot02a/b_u585i_iot02a-common.dtsi:127 */
			st,prescaler = < 0xff >;        /* in zephyr/boards/st/b_u585i_iot02a/b_u585i_iot02a-common.dtsi:128 */

			/* node '/soc/timers@40000400/pwm' defined in zephyr/dts/arm/st/u5/stm32u5.dtsi:622 */
			pwm3: pwm {
				compatible = "st,stm32-pwm";   /* in zephyr/dts/arm/st/u5/stm32u5.dtsi:623 */
				#pwm-cells = < 0x3 >;          /* in zephyr/dts/arm/st/u5/stm32u5.dtsi:625 */
				status = "okay";               /* in zephyr/boards/st/b_u585i_iot02a/b_u585i_iot02a-common.dtsi:131 */
				pinctrl-0 = < &tim3_ch2_pe4 >; /* in zephyr/boards/st/b_u585i_iot02a/b_u585i_iot02a-common.dtsi:132 */
				pinctrl-names = "default";     /* in zephyr/boards/st/b_u585i_iot02a/b_u585i_iot02a-common.dtsi:133 */
			};

			/* node '/soc/timers@40000400/counter' defined in zephyr/dts/arm/st/u5/stm32u5.dtsi:628 */
			counter {
				compatible = "st,stm32-counter"; /* in zephyr/dts/arm/st/u5/stm32u5.dtsi:629 */
				status = "disabled";             /* in zephyr/dts/arm/st/u5/stm32u5.dtsi:630 */
			};

			/* node '/soc/timers@40000400/qdec' defined in zephyr/dts/arm/st/u5/stm32u5.dtsi:633 */
			qdec {
				compatible = "st,stm32-qdec";    /* in zephyr/dts/arm/st/u5/stm32u5.dtsi:634 */
				st,input-filter-level = < 0x0 >; /* in zephyr/dts/arm/st/u5/stm32u5.dtsi:635 */
				status = "disabled";             /* in zephyr/dts/arm/st/u5/stm32u5.dtsi:636 */
			};
		};

		/* node '/soc/timers@40000800' defined in zephyr/dts/arm/st/u5/stm32u5.dtsi:640 */
		timers4: timers@40000800 {
			compatible = "st,stm32-timers"; /* in zephyr/dts/arm/st/u5/stm32u5.dtsi:641 */
			reg = < 0x40000800 0x400 >;     /* in zephyr/dts/arm/st/u5/stm32u5.dtsi:642 */
			clocks = < &rcc 0x9c 0x4 >,
			         < &rcc 0xd 0xff >;     /* in zephyr/dts/arm/st/u5/stm32u5.dtsi:643 */
			resets = < &rctl 0xe82 >;       /* in zephyr/dts/arm/st/u5/stm32u5.dtsi:645 */
			interrupts = < 0x2f 0x0 >;      /* in zephyr/dts/arm/st/u5/stm32u5.dtsi:646 */
			interrupt-names = "global";     /* in zephyr/dts/arm/st/u5/stm32u5.dtsi:647 */
			status = "okay";                /* in zephyr/boards/st/b_u585i_iot02a/b_u585i_iot02a-common.dtsi:116 */
			st,prescaler = < 0x1 >;         /* in zephyr/boards/st/b_u585i_iot02a/b_u585i_iot02a-common.dtsi:117 */

			/* node '/soc/timers@40000800/pwm' defined in zephyr/dts/arm/st/u5/stm32u5.dtsi:650 */
			pwm4: pwm {
				compatible = "st,stm32-pwm";   /* in zephyr/dts/arm/st/u5/stm32u5.dtsi:651 */
				#pwm-cells = < 0x3 >;          /* in zephyr/dts/arm/st/u5/stm32u5.dtsi:653 */
				status = "okay";               /* in zephyr/boards/st/b_u585i_iot02a/b_u585i_iot02a-common.dtsi:120 */
				pinctrl-0 = < &tim4_ch1_pb6 >; /* in zephyr/boards/st/b_u585i_iot02a/b_u585i_iot02a-common.dtsi:121 */
				pinctrl-names = "default";     /* in zephyr/boards/st/b_u585i_iot02a/b_u585i_iot02a-common.dtsi:122 */
			};

			/* node '/soc/timers@40000800/counter' defined in zephyr/dts/arm/st/u5/stm32u5.dtsi:656 */
			counter {
				compatible = "st,stm32-counter"; /* in zephyr/dts/arm/st/u5/stm32u5.dtsi:657 */
				status = "disabled";             /* in zephyr/dts/arm/st/u5/stm32u5.dtsi:658 */
			};

			/* node '/soc/timers@40000800/qdec' defined in zephyr/dts/arm/st/u5/stm32u5.dtsi:661 */
			qdec {
				compatible = "st,stm32-qdec";    /* in zephyr/dts/arm/st/u5/stm32u5.dtsi:662 */
				st,input-filter-level = < 0x0 >; /* in zephyr/dts/arm/st/u5/stm32u5.dtsi:663 */
				status = "disabled";             /* in zephyr/dts/arm/st/u5/stm32u5.dtsi:664 */
			};
		};

		/* node '/soc/timers@40000c00' defined in zephyr/dts/arm/st/u5/stm32u5.dtsi:668 */
		timers5: timers@40000c00 {
			compatible = "st,stm32-timers"; /* in zephyr/dts/arm/st/u5/stm32u5.dtsi:669 */
			reg = < 0x40000c00 0x400 >;     /* in zephyr/dts/arm/st/u5/stm32u5.dtsi:670 */
			clocks = < &rcc 0x9c 0x8 >,
			         < &rcc 0xd 0xff >;     /* in zephyr/dts/arm/st/u5/stm32u5.dtsi:671 */
			resets = < &rctl 0xe83 >;       /* in zephyr/dts/arm/st/u5/stm32u5.dtsi:673 */
			interrupts = < 0x30 0x0 >;      /* in zephyr/dts/arm/st/u5/stm32u5.dtsi:674 */
			interrupt-names = "global";     /* in zephyr/dts/arm/st/u5/stm32u5.dtsi:675 */
			status = "disabled";            /* in zephyr/dts/arm/st/u5/stm32u5.dtsi:676 */

			/* node '/soc/timers@40000c00/pwm' defined in zephyr/dts/arm/st/u5/stm32u5.dtsi:678 */
			pwm {
				compatible = "st,stm32-pwm"; /* in zephyr/dts/arm/st/u5/stm32u5.dtsi:679 */
				status = "disabled";         /* in zephyr/dts/arm/st/u5/stm32u5.dtsi:680 */
				#pwm-cells = < 0x3 >;        /* in zephyr/dts/arm/st/u5/stm32u5.dtsi:681 */
			};

			/* node '/soc/timers@40000c00/counter' defined in zephyr/dts/arm/st/u5/stm32u5.dtsi:684 */
			counter {
				compatible = "st,stm32-counter"; /* in zephyr/dts/arm/st/u5/stm32u5.dtsi:685 */
				status = "disabled";             /* in zephyr/dts/arm/st/u5/stm32u5.dtsi:686 */
			};

			/* node '/soc/timers@40000c00/qdec' defined in zephyr/dts/arm/st/u5/stm32u5.dtsi:689 */
			qdec {
				compatible = "st,stm32-qdec";    /* in zephyr/dts/arm/st/u5/stm32u5.dtsi:690 */
				st,input-filter-level = < 0x0 >; /* in zephyr/dts/arm/st/u5/stm32u5.dtsi:691 */
				status = "disabled";             /* in zephyr/dts/arm/st/u5/stm32u5.dtsi:692 */
			};
		};

		/* node '/soc/timers@40001000' defined in zephyr/dts/arm/st/u5/stm32u5.dtsi:696 */
		timers6: timers@40001000 {
			compatible = "st,stm32-timers"; /* in zephyr/dts/arm/st/u5/stm32u5.dtsi:697 */
			reg = < 0x40001000 0x400 >;     /* in zephyr/dts/arm/st/u5/stm32u5.dtsi:698 */
			clocks = < &rcc 0x9c 0x10 >,
			         < &rcc 0xd 0xff >;     /* in zephyr/dts/arm/st/u5/stm32u5.dtsi:699 */
			resets = < &rctl 0xe84 >;       /* in zephyr/dts/arm/st/u5/stm32u5.dtsi:701 */
			interrupts = < 0x31 0x0 >;      /* in zephyr/dts/arm/st/u5/stm32u5.dtsi:702 */
			interrupt-names = "global";     /* in zephyr/dts/arm/st/u5/stm32u5.dtsi:703 */
			status = "disabled";            /* in zephyr/dts/arm/st/u5/stm32u5.dtsi:704 */

			/* node '/soc/timers@40001000/pwm' defined in zephyr/dts/arm/st/u5/stm32u5.dtsi:706 */
			pwm {
				compatible = "st,stm32-pwm"; /* in zephyr/dts/arm/st/u5/stm32u5.dtsi:707 */
				status = "disabled";         /* in zephyr/dts/arm/st/u5/stm32u5.dtsi:708 */
				#pwm-cells = < 0x3 >;        /* in zephyr/dts/arm/st/u5/stm32u5.dtsi:709 */
			};

			/* node '/soc/timers@40001000/counter' defined in zephyr/dts/arm/st/u5/stm32u5.dtsi:712 */
			counter {
				compatible = "st,stm32-counter"; /* in zephyr/dts/arm/st/u5/stm32u5.dtsi:713 */
				status = "disabled";             /* in zephyr/dts/arm/st/u5/stm32u5.dtsi:714 */
			};
		};

		/* node '/soc/timers@40001400' defined in zephyr/dts/arm/st/u5/stm32u5.dtsi:718 */
		timers7: timers@40001400 {
			compatible = "st,stm32-timers"; /* in zephyr/dts/arm/st/u5/stm32u5.dtsi:719 */
			reg = < 0x40001400 0x400 >;     /* in zephyr/dts/arm/st/u5/stm32u5.dtsi:720 */
			clocks = < &rcc 0x9c 0x20 >,
			         < &rcc 0xd 0xff >;     /* in zephyr/dts/arm/st/u5/stm32u5.dtsi:721 */
			resets = < &rctl 0xe85 >;       /* in zephyr/dts/arm/st/u5/stm32u5.dtsi:723 */
			interrupts = < 0x32 0x0 >;      /* in zephyr/dts/arm/st/u5/stm32u5.dtsi:724 */
			interrupt-names = "global";     /* in zephyr/dts/arm/st/u5/stm32u5.dtsi:725 */
			status = "disabled";            /* in zephyr/dts/arm/st/u5/stm32u5.dtsi:726 */

			/* node '/soc/timers@40001400/pwm' defined in zephyr/dts/arm/st/u5/stm32u5.dtsi:728 */
			pwm {
				compatible = "st,stm32-pwm"; /* in zephyr/dts/arm/st/u5/stm32u5.dtsi:729 */
				status = "disabled";         /* in zephyr/dts/arm/st/u5/stm32u5.dtsi:730 */
				#pwm-cells = < 0x3 >;        /* in zephyr/dts/arm/st/u5/stm32u5.dtsi:731 */
			};

			/* node '/soc/timers@40001400/counter' defined in zephyr/dts/arm/st/u5/stm32u5.dtsi:734 */
			counter {
				compatible = "st,stm32-counter"; /* in zephyr/dts/arm/st/u5/stm32u5.dtsi:735 */
				status = "disabled";             /* in zephyr/dts/arm/st/u5/stm32u5.dtsi:736 */
			};
		};

		/* node '/soc/timers@40013400' defined in zephyr/dts/arm/st/u5/stm32u5.dtsi:740 */
		timers8: timers@40013400 {
			compatible = "st,stm32-timers"; /* in zephyr/dts/arm/st/u5/stm32u5.dtsi:741 */
			reg = < 0x40013400 0x400 >;     /* in zephyr/dts/arm/st/u5/stm32u5.dtsi:742 */
			clocks = < &rcc 0xa4 0x2000 >,
			         < &rcc 0xe 0xff >;     /* in zephyr/dts/arm/st/u5/stm32u5.dtsi:743 */
			resets = < &rctl 0xf8d >;       /* in zephyr/dts/arm/st/u5/stm32u5.dtsi:745 */
			interrupts = < 0x33 0x0 >,
			             < 0x34 0x0 >,
			             < 0x35 0x0 >,
			             < 0x36 0x0 >;      /* in zephyr/dts/arm/st/u5/stm32u5.dtsi:746 */
			interrupt-names = "brk",
			                  "up",
			                  "trgcom",
			                  "cc";         /* in zephyr/dts/arm/st/u5/stm32u5.dtsi:747 */
			status = "disabled";            /* in zephyr/dts/arm/st/u5/stm32u5.dtsi:748 */

			/* node '/soc/timers@40013400/pwm' defined in zephyr/dts/arm/st/u5/stm32u5.dtsi:750 */
			pwm {
				compatible = "st,stm32-pwm"; /* in zephyr/dts/arm/st/u5/stm32u5.dtsi:751 */
				status = "disabled";         /* in zephyr/dts/arm/st/u5/stm32u5.dtsi:752 */
				#pwm-cells = < 0x3 >;        /* in zephyr/dts/arm/st/u5/stm32u5.dtsi:753 */
			};

			/* node '/soc/timers@40013400/counter' defined in zephyr/dts/arm/st/u5/stm32u5.dtsi:756 */
			counter {
				compatible = "st,stm32-counter"; /* in zephyr/dts/arm/st/u5/stm32u5.dtsi:757 */
				status = "disabled";             /* in zephyr/dts/arm/st/u5/stm32u5.dtsi:758 */
			};

			/* node '/soc/timers@40013400/qdec' defined in zephyr/dts/arm/st/u5/stm32u5.dtsi:761 */
			qdec {
				compatible = "st,stm32-qdec";    /* in zephyr/dts/arm/st/u5/stm32u5.dtsi:762 */
				st,input-filter-level = < 0x0 >; /* in zephyr/dts/arm/st/u5/stm32u5.dtsi:763 */
				status = "disabled";             /* in zephyr/dts/arm/st/u5/stm32u5.dtsi:764 */
			};
		};

		/* node '/soc/timers@40014000' defined in zephyr/dts/arm/st/u5/stm32u5.dtsi:768 */
		timers15: timers@40014000 {
			compatible = "st,stm32-timers"; /* in zephyr/dts/arm/st/u5/stm32u5.dtsi:769 */
			reg = < 0x40014000 0x400 >;     /* in zephyr/dts/arm/st/u5/stm32u5.dtsi:770 */
			clocks = < &rcc 0xa4 0x10000 >,
			         < &rcc 0xe 0xff >;     /* in zephyr/dts/arm/st/u5/stm32u5.dtsi:771 */
			resets = < &rctl 0xf90 >;       /* in zephyr/dts/arm/st/u5/stm32u5.dtsi:773 */
			interrupts = < 0x45 0x0 >;      /* in zephyr/dts/arm/st/u5/stm32u5.dtsi:774 */
			interrupt-names = "global";     /* in zephyr/dts/arm/st/u5/stm32u5.dtsi:775 */
			status = "disabled";            /* in zephyr/dts/arm/st/u5/stm32u5.dtsi:776 */

			/* node '/soc/timers@40014000/pwm' defined in zephyr/dts/arm/st/u5/stm32u5.dtsi:778 */
			pwm {
				compatible = "st,stm32-pwm"; /* in zephyr/dts/arm/st/u5/stm32u5.dtsi:779 */
				status = "disabled";         /* in zephyr/dts/arm/st/u5/stm32u5.dtsi:780 */
				#pwm-cells = < 0x3 >;        /* in zephyr/dts/arm/st/u5/stm32u5.dtsi:781 */
			};

			/* node '/soc/timers@40014000/counter' defined in zephyr/dts/arm/st/u5/stm32u5.dtsi:784 */
			counter {
				compatible = "st,stm32-counter"; /* in zephyr/dts/arm/st/u5/stm32u5.dtsi:785 */
				status = "disabled";             /* in zephyr/dts/arm/st/u5/stm32u5.dtsi:786 */
			};
		};

		/* node '/soc/timers@40014400' defined in zephyr/dts/arm/st/u5/stm32u5.dtsi:790 */
		timers16: timers@40014400 {
			compatible = "st,stm32-timers"; /* in zephyr/dts/arm/st/u5/stm32u5.dtsi:791 */
			reg = < 0x40014400 0x400 >;     /* in zephyr/dts/arm/st/u5/stm32u5.dtsi:792 */
			clocks = < &rcc 0xa4 0x20000 >,
			         < &rcc 0xe 0xff >;     /* in zephyr/dts/arm/st/u5/stm32u5.dtsi:793 */
			resets = < &rctl 0xf91 >;       /* in zephyr/dts/arm/st/u5/stm32u5.dtsi:795 */
			interrupts = < 0x46 0x0 >;      /* in zephyr/dts/arm/st/u5/stm32u5.dtsi:796 */
			interrupt-names = "global";     /* in zephyr/dts/arm/st/u5/stm32u5.dtsi:797 */
			status = "disabled";            /* in zephyr/dts/arm/st/u5/stm32u5.dtsi:798 */

			/* node '/soc/timers@40014400/pwm' defined in zephyr/dts/arm/st/u5/stm32u5.dtsi:800 */
			pwm {
				compatible = "st,stm32-pwm"; /* in zephyr/dts/arm/st/u5/stm32u5.dtsi:801 */
				status = "disabled";         /* in zephyr/dts/arm/st/u5/stm32u5.dtsi:802 */
				#pwm-cells = < 0x3 >;        /* in zephyr/dts/arm/st/u5/stm32u5.dtsi:803 */
			};

			/* node '/soc/timers@40014400/counter' defined in zephyr/dts/arm/st/u5/stm32u5.dtsi:806 */
			counter {
				compatible = "st,stm32-counter"; /* in zephyr/dts/arm/st/u5/stm32u5.dtsi:807 */
				status = "disabled";             /* in zephyr/dts/arm/st/u5/stm32u5.dtsi:808 */
			};
		};

		/* node '/soc/timers@40014800' defined in zephyr/dts/arm/st/u5/stm32u5.dtsi:812 */
		timers17: timers@40014800 {
			compatible = "st,stm32-timers"; /* in zephyr/dts/arm/st/u5/stm32u5.dtsi:813 */
			reg = < 0x40014800 0x400 >;     /* in zephyr/dts/arm/st/u5/stm32u5.dtsi:814 */
			clocks = < &rcc 0xa4 0x40000 >,
			         < &rcc 0xe 0xff >;     /* in zephyr/dts/arm/st/u5/stm32u5.dtsi:815 */
			resets = < &rctl 0xf92 >;       /* in zephyr/dts/arm/st/u5/stm32u5.dtsi:817 */
			interrupts = < 0x47 0x0 >;      /* in zephyr/dts/arm/st/u5/stm32u5.dtsi:818 */
			interrupt-names = "global";     /* in zephyr/dts/arm/st/u5/stm32u5.dtsi:819 */
			status = "disabled";            /* in zephyr/dts/arm/st/u5/stm32u5.dtsi:820 */

			/* node '/soc/timers@40014800/pwm' defined in zephyr/dts/arm/st/u5/stm32u5.dtsi:822 */
			pwm {
				compatible = "st,stm32-pwm"; /* in zephyr/dts/arm/st/u5/stm32u5.dtsi:823 */
				status = "disabled";         /* in zephyr/dts/arm/st/u5/stm32u5.dtsi:824 */
				#pwm-cells = < 0x3 >;        /* in zephyr/dts/arm/st/u5/stm32u5.dtsi:825 */
			};

			/* node '/soc/timers@40014800/counter' defined in zephyr/dts/arm/st/u5/stm32u5.dtsi:828 */
			counter {
				compatible = "st,stm32-counter"; /* in zephyr/dts/arm/st/u5/stm32u5.dtsi:829 */
				status = "disabled";             /* in zephyr/dts/arm/st/u5/stm32u5.dtsi:830 */
			};
		};

		/* node '/soc/spi@420d1400' defined in zephyr/dts/arm/st/u5/stm32u5.dtsi:834 */
		octospi1: spi@420d1400 {
			compatible = "st,stm32-ospi";                                                                       /* in zephyr/dts/arm/st/u5/stm32u5.dtsi:835 */
			reg = < 0x420d1400 0x400 >,
			      < 0x90000000 0x10000000 >;                                                                    /* in zephyr/dts/arm/st/u5/stm32u5.dtsi:836 */
			interrupts = < 0x4c 0x0 >;                                                                          /* in zephyr/dts/arm/st/u5/stm32u5.dtsi:837 */
			clock-names = "ospix",
			              "ospi-ker",
			              "ospi-mgr";                                                                           /* in zephyr/dts/arm/st/u5/stm32u5.dtsi:838 */
			clocks = < &rcc 0x90 0x10 >,
			         < &rcc 0x1 0x3400e4 >,
			         < &rcc 0x8c 0x200000 >;                                                                    /* in zephyr/dts/arm/st/u5/stm32u5.dtsi:839 */
			#address-cells = < 0x1 >;                                                                           /* in zephyr/dts/arm/st/u5/stm32u5.dtsi:842 */
			#size-cells = < 0x0 >;                                                                              /* in zephyr/dts/arm/st/u5/stm32u5.dtsi:843 */
			pinctrl-0 = < &octospim_p1_clk_pb10 &octospim_p1_ncs_pb11 &octospim_p1_io0_pf8 &octospim_p1_io1_pf9
			              &octospim_p1_io2_pf7 &octospim_p1_io3_pf6 &octospim_p1_io4_ph2 &octospim_p1_io5_pi0
			              &octospim_p1_io6_pc3 &octospim_p1_io7_pd7 &octospim_p1_dqs_pe3 >;                     /* in zephyr/boards/st/b_u585i_iot02a/b_u585i_iot02a-common.dtsi:138 */
			pinctrl-names = "default";                                                                          /* in zephyr/boards/st/b_u585i_iot02a/b_u585i_iot02a-common.dtsi:144 */
			status = "okay";                                                                                    /* in zephyr/boards/st/b_u585i_iot02a/b_u585i_iot02a-common.dtsi:145 */

			/* node '/soc/spi@420d1400/memory@0' defined in zephyr/boards/st/b_u585i_iot02a/b_u585i_iot02a-common.dtsi:147 */
			memc: aps6408l: memory@0 {
				compatible = "st,stm32-ospi-psram"; /* in zephyr/boards/st/b_u585i_iot02a/b_u585i_iot02a-common.dtsi:148 */
				reg = < 0x0 >;                      /* in zephyr/boards/st/b_u585i_iot02a/b_u585i_iot02a-common.dtsi:149 */
				size = < 0x4000000 >;               /* in zephyr/boards/st/b_u585i_iot02a/b_u585i_iot02a-common.dtsi:150 */
				max-frequency = < 0x7ed6b40 >;      /* in zephyr/boards/st/b_u585i_iot02a/b_u585i_iot02a-common.dtsi:151 */
				fixed-latency;                      /* in zephyr/boards/st/b_u585i_iot02a/b_u585i_iot02a-common.dtsi:152 */
				burst-length = < 0x3 >;             /* in zephyr/boards/st/b_u585i_iot02a/b_u585i_iot02a-common.dtsi:153 */
				st,csbound = < 0xa >;               /* in zephyr/boards/st/b_u585i_iot02a/b_u585i_iot02a-common.dtsi:154 */
				st,refresh = < 0x140 >;             /* in zephyr/boards/st/b_u585i_iot02a/b_u585i_iot02a-common.dtsi:155 */
				status = "okay";                    /* in zephyr/boards/st/b_u585i_iot02a/b_u585i_iot02a-common.dtsi:156 */
			};
		};

		/* node '/soc/spi@420d2400' defined in zephyr/dts/arm/st/u5/stm32u5.dtsi:847 */
		octospi2: spi@420d2400 {
			compatible = "st,stm32-ospi";                                                                      /* in zephyr/dts/arm/st/u5/stm32u5_extra.dtsi:59 */
			reg = < 0x420d2400 0x400 >,
			      < 0x70000000 0x10000000 >;                                                                   /* in zephyr/dts/arm/st/u5/stm32u5_extra.dtsi:60 */
			interrupts = < 0x78 0x0 >;                                                                         /* in zephyr/dts/arm/st/u5/stm32u5_extra.dtsi:61 */
			clock-names = "ospix",
			              "ospi-ker",
			              "ospi-mgr";                                                                          /* in zephyr/dts/arm/st/u5/stm32u5_extra.dtsi:62 */
			clocks = < &rcc 0x90 0x100 >,
			         < &rcc 0x1 0x3400e4 >,
			         < &rcc 0x8c 0x200000 >;                                                                   /* in zephyr/dts/arm/st/u5/stm32u5_extra.dtsi:63 */
			#address-cells = < 0x1 >;                                                                          /* in zephyr/dts/arm/st/u5/stm32u5_extra.dtsi:66 */
			#size-cells = < 0x0 >;                                                                             /* in zephyr/dts/arm/st/u5/stm32u5_extra.dtsi:67 */
			pinctrl-0 = < &octospim_p2_clk_pf4 &octospim_p2_ncs_pi5 &octospim_p2_io0_pf0 &octospim_p2_io1_pf1
			              &octospim_p2_io2_pf2 &octospim_p2_io3_pf3 &octospim_p2_io4_ph9 &octospim_p2_io5_ph10
			              &octospim_p2_io6_ph11 &octospim_p2_io7_ph12 &octospim_p2_dqs_pf12 >;                 /* in zephyr/boards/st/b_u585i_iot02a/b_u585i_iot02a-common.dtsi:161 */
			pinctrl-names = "default";                                                                         /* in zephyr/boards/st/b_u585i_iot02a/b_u585i_iot02a-common.dtsi:167 */
			status = "okay";                                                                                   /* in zephyr/boards/st/b_u585i_iot02a/b_u585i_iot02a-common.dtsi:169 */

			/* node '/soc/spi@420d2400/ospi-flash-controller@0' defined in zephyr/boards/st/b_u585i_iot02a/b_u585i_iot02a-common.dtsi:171 */
			ext_flash_ctrl: ospi-flash-controller@0 {
				compatible = "st,stm32-ospi-nor";      /* in zephyr/boards/st/b_u585i_iot02a/b_u585i_iot02a-common.dtsi:172 */
				reg = < 0x0 >;                         /* in zephyr/boards/st/b_u585i_iot02a/b_u585i_iot02a-common.dtsi:173 */
				size = < 0x20000000 >;                 /* in zephyr/boards/st/b_u585i_iot02a/b_u585i_iot02a-common.dtsi:174 */
				ospi-max-frequency = < 0x2faf080 >;    /* in zephyr/boards/st/b_u585i_iot02a/b_u585i_iot02a-common.dtsi:175 */
				spi-bus-width = < 0x8 >;               /* in zephyr/boards/st/b_u585i_iot02a/b_u585i_iot02a-common.dtsi:176 */
				data-rate = < 0x2 >;                   /* in zephyr/boards/st/b_u585i_iot02a/b_u585i_iot02a-common.dtsi:177 */
				four-byte-opcodes;                     /* in zephyr/boards/st/b_u585i_iot02a/b_u585i_iot02a-common.dtsi:178 */
				status = "okay";                       /* in zephyr/boards/st/b_u585i_iot02a/b_u585i_iot02a-common.dtsi:179 */
				#address-cells = < 0x1 >;              /* in zephyr/boards/st/b_u585i_iot02a/b_u585i_iot02a-common.dtsi:181 */
				#size-cells = < 0x1 >;                 /* in zephyr/boards/st/b_u585i_iot02a/b_u585i_iot02a-common.dtsi:182 */
				ranges = < 0x0 0x70000000 0x4000000 >; /* in zephyr/boards/st/b_u585i_iot02a/b_u585i_iot02a-common.dtsi:184 */

				/* node '/soc/spi@420d2400/ospi-flash-controller@0/ext-flash@0' defined in zephyr/boards/st/b_u585i_iot02a/b_u585i_iot02a-common.dtsi:186 */
				ext_flash: mx25lm51245: ext-flash@0 {
					compatible = "soc-nv-flash";   /* in zephyr/boards/st/b_u585i_iot02a/b_u585i_iot02a-common.dtsi:187 */
					reg = < 0x0 0x4000000 >;       /* in zephyr/boards/st/b_u585i_iot02a/b_u585i_iot02a-common.dtsi:188 */
					write-block-size = < 0x1 >;    /* in zephyr/boards/st/b_u585i_iot02a/b_u585i_iot02a-common.dtsi:189 */
					erase-block-size = < 0x1000 >; /* in zephyr/boards/st/b_u585i_iot02a/b_u585i_iot02a-common.dtsi:190 */

					/* node '/soc/spi@420d2400/ospi-flash-controller@0/ext-flash@0/partitions' defined in zephyr/boards/st/b_u585i_iot02a/b_u585i_iot02a.dts:86 */
					partitions {
						compatible = "fixed-partitions"; /* in zephyr/boards/st/b_u585i_iot02a/b_u585i_iot02a.dts:87 */
						#address-cells = < 0x1 >;        /* in zephyr/boards/st/b_u585i_iot02a/b_u585i_iot02a.dts:88 */
						#size-cells = < 0x1 >;           /* in zephyr/boards/st/b_u585i_iot02a/b_u585i_iot02a.dts:89 */

						/* node '/soc/spi@420d2400/ospi-flash-controller@0/ext-flash@0/partitions/partition@0' defined in zephyr/boards/st/b_u585i_iot02a/b_u585i_iot02a.dts:91 */
						partition@0 {
							reg = < 0x0 0x4000000 >; /* in zephyr/boards/st/b_u585i_iot02a/b_u585i_iot02a.dts:92 */
						};
					};
				};
			};
		};

		/* node '/soc/rng@420c0800' defined in zephyr/dts/arm/st/u5/stm32u5.dtsi:860 */
		rng: rng@420c0800 {
			compatible = "st,stm32-rng";        /* in zephyr/dts/arm/st/u5/stm32u5.dtsi:861 */
			reg = < 0x420c0800 0x400 >;         /* in zephyr/dts/arm/st/u5/stm32u5.dtsi:862 */
			clocks = < &rcc 0x8c 0x40000 >;     /* in zephyr/dts/arm/st/u5/stm32u5.dtsi:863 */
			interrupts = < 0x5e 0x0 >;          /* in zephyr/dts/arm/st/u5/stm32u5.dtsi:864 */
			nist-config = < 0xf00d00 >;         /* in zephyr/dts/arm/st/u5/stm32u575.dtsi:26 */
			health-test-config = < 0xa2b0 >;    /* in zephyr/dts/arm/st/u5/stm32u575.dtsi:27 */
			noise-source-control = < 0x17cbb >; /* in zephyr/dts/arm/st/u5/stm32u575.dtsi:28 */
			status = "okay";                    /* in zephyr/boards/st/b_u585i_iot02a/b_u585i_iot02a.dts:123 */
		};

		/* node '/soc/sdmmc@420c8000' defined in zephyr/dts/arm/st/u5/stm32u5.dtsi:877 */
		sdmmc1: sdmmc@420c8000 {
			compatible = "st,stm32-sdmmc";    /* in zephyr/dts/arm/st/u5/stm32u5.dtsi:878 */
			reg = < 0x420c8000 0x400 >;       /* in zephyr/dts/arm/st/u5/stm32u5.dtsi:879 */
			clocks = < &rcc 0x8c 0x8000000 >,
			         < &rcc 0x6 0xe00e4 >;    /* in zephyr/dts/arm/st/u5/stm32u5.dtsi:880 */
			resets = < &rctl 0xc9b >;         /* in zephyr/dts/arm/st/u5/stm32u5.dtsi:882 */
			interrupts = < 0x4e 0x0 >;        /* in zephyr/dts/arm/st/u5/stm32u5.dtsi:883 */
			status = "disabled";              /* in zephyr/dts/arm/st/u5/stm32u5.dtsi:884 */
		};

		/* node '/soc/dac@46021800' defined in zephyr/dts/arm/st/u5/stm32u5.dtsi:887 */
		dac1: dac@46021800 {
			compatible = "st,stm32-dac";    /* in zephyr/dts/arm/st/u5/stm32u5.dtsi:888 */
			reg = < 0x46021800 0x400 >;     /* in zephyr/dts/arm/st/u5/stm32u5.dtsi:889 */
			clocks = < &rcc 0x94 0x40 >;    /* in zephyr/dts/arm/st/u5/stm32u5.dtsi:890 */
			#io-channel-cells = < 0x1 >;    /* in zephyr/dts/arm/st/u5/stm32u5.dtsi:892 */
			pinctrl-0 = < &dac1_out1_pa4 >; /* in zephyr/boards/st/b_u585i_iot02a/b_u585i_iot02a-common.dtsi:279 */
			pinctrl-names = "default";      /* in zephyr/boards/st/b_u585i_iot02a/b_u585i_iot02a-common.dtsi:280 */
			status = "okay";                /* in zephyr/boards/st/b_u585i_iot02a/b_u585i_iot02a-common.dtsi:281 */
		};

		/* node '/soc/adc@42028000' defined in zephyr/dts/arm/st/u5/stm32u5.dtsi:895 */
		adc1: adc@42028000 {
			compatible = "st,stm32-adc";                                 /* in zephyr/dts/arm/st/u5/stm32u5.dtsi:896 */
			reg = < 0x42028000 0x400 >;                                  /* in zephyr/dts/arm/st/u5/stm32u5.dtsi:897 */
			clocks = < &rcc 0x8c 0x400 >,
			         < &rcc 0x9 0x4c00e8 >;                              /* in zephyr/dts/arm/st/u5/stm32u5.dtsi:898 */
			clock-names = "adcx",
			              "adc_ker";                                     /* in zephyr/dts/arm/st/u5/stm32u5.dtsi:900 */
			interrupts = < 0x25 0x0 >;                                   /* in zephyr/dts/arm/st/u5/stm32u5.dtsi:901 */
			#io-channel-cells = < 0x1 >;                                 /* in zephyr/dts/arm/st/u5/stm32u5.dtsi:902 */
			st,adc-resolutions = < 0xe 0xc 0xa 0x8 >;                    /* in zephyr/dts/arm/st/u5/stm32u5.dtsi:903 */
			sampling-times = < 0x5 0x6 0xc 0x14 0x24 0x44 0x187 0x32e >; /* in zephyr/dts/arm/st/u5/stm32u5.dtsi:904 */
			st,adc-sequencer = "programmable";                           /* in zephyr/dts/arm/st/u5/stm32u5.dtsi:906 */
			st,adc-oversampler = "extended";                             /* in zephyr/dts/arm/st/u5/stm32u5.dtsi:907 */
			st,adc-internal-regulator = "startup-hw-status";             /* in zephyr/dts/arm/st/u5/stm32u5.dtsi:908 */
			st,adc-has-deep-powerdown;                                   /* in zephyr/dts/arm/st/u5/stm32u5.dtsi:909 */
			st,adc-has-channel-preselection;                             /* in zephyr/dts/arm/st/u5/stm32u5.dtsi:910 */
			st,adc-has-differential-support;                             /* in zephyr/dts/arm/st/u5/stm32u5.dtsi:911 */
			st,adc-has-injected-support;                                 /* in zephyr/dts/arm/st/u5/stm32u5.dtsi:912 */
			pinctrl-0 = < &adc1_in15_pb0 >;                              /* in zephyr/boards/st/b_u585i_iot02a/b_u585i_iot02a-common.dtsi:259 */
			pinctrl-names = "default";                                   /* in zephyr/boards/st/b_u585i_iot02a/b_u585i_iot02a-common.dtsi:260 */
			st,adc-clock-source = "ASYNC";                               /* in zephyr/boards/st/b_u585i_iot02a/b_u585i_iot02a-common.dtsi:261 */
			st,adc-prescaler = < 0x4 >;                                  /* in zephyr/boards/st/b_u585i_iot02a/b_u585i_iot02a.dts:118 */
			status = "okay";                                             /* in zephyr/boards/st/b_u585i_iot02a/b_u585i_iot02a.dts:119 */
			phandle = < 0x49 >;                                          /* in zephyr/dts/arm/st/u5/stm32u5.dtsi:1078 */
		};

		/* node '/soc/adc@46021000' defined in zephyr/dts/arm/st/u5/stm32u5.dtsi:916 */
		adc4: adc@46021000 {
			compatible = "st,stm32-adc";                               /* in zephyr/dts/arm/st/u5/stm32u5.dtsi:917 */
			reg = < 0x46021000 0x400 >;                                /* in zephyr/dts/arm/st/u5/stm32u5.dtsi:918 */
			clocks = < &rcc 0x94 0x20 >,
			         < &rcc 0x9 0x4c00e8 >;                            /* in zephyr/dts/arm/st/u5/stm32u5.dtsi:919 */
			clock-names = "adcx",
			              "adc_ker";                                   /* in zephyr/dts/arm/st/u5/stm32u5.dtsi:921 */
			interrupts = < 0x71 0x0 >;                                 /* in zephyr/dts/arm/st/u5/stm32u5.dtsi:922 */
			#io-channel-cells = < 0x1 >;                               /* in zephyr/dts/arm/st/u5/stm32u5.dtsi:923 */
			st,adc-resolutions = < 0xc 0xa 0x8 0x6 >;                  /* in zephyr/dts/arm/st/u5/stm32u5.dtsi:924 */
			sampling-times = < 0x2 0x4 0x8 0xd 0x14 0x28 0x50 0x32f >; /* in zephyr/dts/arm/st/u5/stm32u5.dtsi:925 */
			num-sampling-time-common-channels = < 0x2 >;               /* in zephyr/dts/arm/st/u5/stm32u5.dtsi:926 */
			st,adc-sequencer = "fixed";                                /* in zephyr/dts/arm/st/u5/stm32u5.dtsi:928 */
			st,adc-oversampler = "minimal";                            /* in zephyr/dts/arm/st/u5/stm32u5.dtsi:929 */
			st,adc-internal-regulator = "startup-hw-status";           /* in zephyr/dts/arm/st/u5/stm32u5.dtsi:930 */
			pinctrl-0 = < &adc4_in19_pb1 >;                            /* in zephyr/boards/st/b_u585i_iot02a/b_u585i_iot02a-common.dtsi:267 */
			pinctrl-names = "default";                                 /* in zephyr/boards/st/b_u585i_iot02a/b_u585i_iot02a-common.dtsi:268 */
			st,adc-clock-source = "ASYNC";                             /* in zephyr/boards/st/b_u585i_iot02a/b_u585i_iot02a-common.dtsi:269 */
			st,adc-prescaler = < 0x4 >;                                /* in zephyr/boards/st/b_u585i_iot02a/b_u585i_iot02a-common.dtsi:270 */
			status = "okay";                                           /* in zephyr/boards/st/b_u585i_iot02a/b_u585i_iot02a-common.dtsi:271 */
			phandle = < 0x4b >;                                        /* in zephyr/dts/arm/st/u5/stm32u5.dtsi:1096 */
		};

		/* node '/soc/can@4000a400' defined in zephyr/dts/arm/st/u5/stm32u5.dtsi:934 */
		fdcan1: can@4000a400 {
			compatible = "st,stm32-fdcan";                         /* in zephyr/dts/arm/st/u5/stm32u5.dtsi:935 */
			reg = < 0x4000a400 0x400 >,
			      < 0x4000ac00 0x350 >;                            /* in zephyr/dts/arm/st/u5/stm32u5.dtsi:936 */
			reg-names = "m_can",
			            "message_ram";                             /* in zephyr/dts/arm/st/u5/stm32u5.dtsi:937 */
			interrupts = < 0x27 0x0 >,
			             < 0x28 0x0 >;                             /* in zephyr/dts/arm/st/u5/stm32u5.dtsi:938 */
			interrupt-names = "int0",
			                  "int1";                              /* in zephyr/dts/arm/st/u5/stm32u5.dtsi:939 */
			clocks = < &rcc 0xa0 0x200 >;                          /* in zephyr/dts/arm/st/u5/stm32u5.dtsi:940 */
			bosch,mram-cfg = < 0x0 0x1c 0x8 0x3 0x3 0x0 0x3 0x3 >; /* in zephyr/dts/arm/st/u5/stm32u5.dtsi:941 */
			status = "disabled";                                   /* in zephyr/dts/arm/st/u5/stm32u5.dtsi:942 */
		};

		/* node '/soc/dma@40020000' defined in zephyr/dts/arm/st/u5/stm32u5.dtsi:945 */
		gpdma1: dma@40020000 {
			compatible = "st,stm32u5-dma";                                                                  /* in zephyr/dts/arm/st/u5/stm32u5.dtsi:946 */
			#dma-cells = < 0x3 >;                                                                           /* in zephyr/dts/arm/st/u5/stm32u5.dtsi:947 */
			reg = < 0x40020000 0x400 >;                                                                     /* in zephyr/dts/arm/st/u5/stm32u5.dtsi:948 */
			interrupts = < 0x1d 0x0 0x1e 0x0 0x1f 0x0 0x20 0x0 0x21 0x0 0x22 0x0 0x23 0x0 0x24 0x0 0x50 0x0
			               0x51 0x0 0x52 0x0 0x53 0x0 0x54 0x0 0x55 0x0 0x56 0x0 0x57 0x0 >;                /* in zephyr/dts/arm/st/u5/stm32u5.dtsi:949 */
			clocks = < &rcc 0x88 0x1 >;                                                                     /* in zephyr/dts/arm/st/u5/stm32u5.dtsi:951 */
			dma-channels = < 0x10 >;                                                                        /* in zephyr/dts/arm/st/u5/stm32u5.dtsi:952 */
			dma-requests = < 0x72 >;                                                                        /* in zephyr/dts/arm/st/u5/stm32u5.dtsi:953 */
			dma-offset = < 0x0 >;                                                                           /* in zephyr/dts/arm/st/u5/stm32u5.dtsi:954 */
			status = "okay";                                                                                /* in zephyr/boards/st/b_u585i_iot02a/b_u585i_iot02a.dts:98 */
			phandle = < 0x16 >;                                                                             /* in zephyr/dts/arm/st/u5/stm32u5.dtsi:539 */
		};

		/* node '/soc/hash@420c0400' defined in zephyr/dts/arm/st/u5/stm32u5.dtsi:958 */
		hash: hash@420c0400 {
			compatible = "st,stm32-hash";   /* in zephyr/dts/arm/st/u5/stm32u5.dtsi:959 */
			reg = < 0x420c0400 0x400 >;     /* in zephyr/dts/arm/st/u5/stm32u5.dtsi:960 */
			clocks = < &rcc 0x8c 0x20000 >; /* in zephyr/dts/arm/st/u5/stm32u5.dtsi:961 */
			resets = < &rctl 0xc91 >;       /* in zephyr/dts/arm/st/u5/stm32u5.dtsi:962 */
			status = "disabled";            /* in zephyr/dts/arm/st/u5/stm32u5.dtsi:963 */
		};

		/* node '/soc/vrefbuf@46007400' defined in zephyr/dts/arm/st/u5/stm32u5.dtsi:966 */
		vrefbuf: vrefbuf@46007400 {
			compatible = "st,stm32-vrefbuf"; /* in zephyr/dts/arm/st/u5/stm32u5.dtsi:967 */
			reg = < 0x46007400 0x400 >;      /* in zephyr/dts/arm/st/u5/stm32u5.dtsi:968 */
			clocks = < &rcc 0xa8 0x100000 >; /* in zephyr/dts/arm/st/u5/stm32u5.dtsi:969 */
			resets = < &rctl 0x1014 >;       /* in zephyr/dts/arm/st/u5/stm32u5.dtsi:970 */
			ref-voltages = < 0x16e360 >,
			               < 0x1b7740 >,
			               < 0x1f4000 >,
			               < 0x2625a0 >;     /* in zephyr/dts/arm/st/u5/stm32u5.dtsi:971 */
			status = "disabled";             /* in zephyr/dts/arm/st/u5/stm32u5.dtsi:972 */
		};

		/* node '/soc/power@46020800' defined in zephyr/dts/arm/st/u5/stm32u5.dtsi:975 */
		pwr: power@46020800 {
			compatible = "st,stm32u5-pwr",
			             "st,stm32-dualreg-pwr",
			             "st,stm32-pwr";         /* in zephyr/dts/arm/st/u5/stm32u5.dtsi:976 */
			reg = < 0x46020800 0x400 >;          /* in zephyr/dts/arm/st/u5/stm32u5.dtsi:977 */
			status = "disabled";                 /* in zephyr/dts/arm/st/u5/stm32u5.dtsi:978 */
			power-supply = "ldo";                /* in zephyr/dts/arm/st/u5/stm32u5.dtsi:985 */
			wkup-pins-nb = < 0x8 >;              /* in zephyr/dts/arm/st/u5/stm32u5.dtsi:987 */
			wkup-pin-srcs = < 0x3 >;             /* in zephyr/dts/arm/st/u5/stm32u5.dtsi:988 */
			wkup-pins-pol;                       /* in zephyr/dts/arm/st/u5/stm32u5.dtsi:989 */
			wkup-pins-pupd;                      /* in zephyr/dts/arm/st/u5/stm32u5.dtsi:990 */
			#address-cells = < 0x1 >;            /* in zephyr/dts/arm/st/u5/stm32u5.dtsi:992 */
			#size-cells = < 0x0 >;               /* in zephyr/dts/arm/st/u5/stm32u5.dtsi:993 */

			/* node '/soc/power@46020800/wkup-pin@1' defined in zephyr/dts/arm/st/u5/stm32u5.dtsi:995 */
			wkup-pin@1 {
				reg = < 0x1 >;                   /* in zephyr/dts/arm/st/u5/stm32u5.dtsi:996 */
				wkup-gpios = < &gpioa 0x0 0x1 >,
				             < &gpiob 0x2 0x2 >,
				             < &gpioe 0x4 0x4 >; /* in zephyr/dts/arm/st/u5/stm32u5.dtsi:997 */
			};

			/* node '/soc/power@46020800/wkup-pin@2' defined in zephyr/dts/arm/st/u5/stm32u5.dtsi:1002 */
			wkup-pin@2 {
				reg = < 0x2 >;                   /* in zephyr/dts/arm/st/u5/stm32u5.dtsi:1003 */
				wkup-gpios = < &gpioa 0x4 0x1 >,
				             < &gpioc 0xd 0x2 >,
				             < &gpioe 0x5 0x4 >; /* in zephyr/dts/arm/st/u5/stm32u5.dtsi:1004 */
			};

			/* node '/soc/power@46020800/wkup-pin@3' defined in zephyr/dts/arm/st/u5/stm32u5.dtsi:1009 */
			wkup-pin@3 {
				reg = < 0x3 >;                   /* in zephyr/dts/arm/st/u5/stm32u5.dtsi:1010 */
				wkup-gpios = < &gpioe 0x6 0x1 >,
				             < &gpioa 0x1 0x2 >,
				             < &gpiob 0x6 0x4 >; /* in zephyr/dts/arm/st/u5/stm32u5.dtsi:1011 */
			};

			/* node '/soc/power@46020800/wkup-pin@4' defined in zephyr/dts/arm/st/u5/stm32u5.dtsi:1016 */
			wkup-pin@4 {
				reg = < 0x4 >;                   /* in zephyr/dts/arm/st/u5/stm32u5.dtsi:1017 */
				wkup-gpios = < &gpioa 0x2 0x1 >,
				             < &gpiob 0x1 0x2 >,
				             < &gpiob 0x7 0x4 >; /* in zephyr/dts/arm/st/u5/stm32u5.dtsi:1018 */
			};

			/* node '/soc/power@46020800/wkup-pin@5' defined in zephyr/dts/arm/st/u5/stm32u5.dtsi:1023 */
			wkup-pin@5 {
				reg = < 0x5 >;                   /* in zephyr/dts/arm/st/u5/stm32u5.dtsi:1024 */
				wkup-gpios = < &gpioc 0x5 0x1 >,
				             < &gpioa 0x3 0x2 >,
				             < &gpiob 0x8 0x4 >; /* in zephyr/dts/arm/st/u5/stm32u5.dtsi:1025 */
			};

			/* node '/soc/power@46020800/wkup-pin@6' defined in zephyr/dts/arm/st/u5/stm32u5.dtsi:1030 */
			wkup-pin@6 {
				reg = < 0x6 >;                   /* in zephyr/dts/arm/st/u5/stm32u5.dtsi:1031 */
				wkup-gpios = < &gpiob 0x5 0x1 >,
				             < &gpioa 0x5 0x2 >,
				             < &gpioe 0x7 0x4 >; /* in zephyr/dts/arm/st/u5/stm32u5.dtsi:1032 */
			};

			/* node '/soc/power@46020800/wkup-pin@7' defined in zephyr/dts/arm/st/u5/stm32u5.dtsi:1037 */
			wkup-pin@7 {
				reg = < 0x7 >;                   /* in zephyr/dts/arm/st/u5/stm32u5.dtsi:1038 */
				wkup-gpios = < &gpiob 0xf 0x1 >,
				             < &gpioa 0x6 0x2 >,
				             < &gpioe 0x8 0x4 >; /* in zephyr/dts/arm/st/u5/stm32u5.dtsi:1039 */
			};

			/* node '/soc/power@46020800/wkup-pin@8' defined in zephyr/dts/arm/st/u5/stm32u5.dtsi:1044 */
			wkup-pin@8 {
				reg = < 0x8 >;                   /* in zephyr/dts/arm/st/u5/stm32u5.dtsi:1045 */
				wkup-gpios = < &gpiof 0x2 0x1 >,
				             < &gpioa 0x7 0x2 >,
				             < &gpiob 0xa 0x4 >; /* in zephyr/dts/arm/st/u5/stm32u5_extra.dtsi:83 */
			};
		};

		/* node '/soc/crc@40023000' defined in zephyr/dts/arm/st/u5/stm32u5.dtsi:1051 */
		crc: crc@40023000 {
			compatible = "st,stm32-crc";   /* in zephyr/dts/arm/st/u5/stm32u5.dtsi:1052 */
			reg = < 0x40023000 0x400 >;    /* in zephyr/dts/arm/st/u5/stm32u5.dtsi:1053 */
			clocks = < &rcc 0x88 0x1000 >; /* in zephyr/dts/arm/st/u5/stm32u5.dtsi:1054 */
			resets = < &rctl 0xc0c >;      /* in zephyr/dts/arm/st/u5/stm32u5.dtsi:1055 */
			status = "okay";               /* in zephyr/boards/st/b_u585i_iot02a/b_u585i_iot02a-common.dtsi:303 */
		};

		/* node '/soc/serial@40004400' defined in zephyr/dts/arm/st/u5/stm32u5_extra.dtsi:9 */
		usart2: serial@40004400 {
			compatible = "st,stm32-usart",
			             "st,stm32-uart";   /* in zephyr/dts/arm/st/u5/stm32u5_extra.dtsi:10 */
			reg = < 0x40004400 0x400 >;     /* in zephyr/dts/arm/st/u5/stm32u5_extra.dtsi:11 */
			clocks = < &rcc 0x9c 0x20000 >; /* in zephyr/dts/arm/st/u5/stm32u5_extra.dtsi:12 */
			resets = < &rctl 0xe91 >;       /* in zephyr/dts/arm/st/u5/stm32u5_extra.dtsi:13 */
			interrupts = < 0x3e 0x0 >;      /* in zephyr/dts/arm/st/u5/stm32u5_extra.dtsi:14 */
			status = "disabled";            /* in zephyr/dts/arm/st/u5/stm32u5_extra.dtsi:15 */
		};

		/* node '/soc/gpio@42021400' defined in zephyr/dts/arm/st/u5/stm32u5_extra.dtsi:18 */
		gpiof: gpio@42021400 {
			compatible = "st,stm32-gpio"; /* in zephyr/dts/arm/st/u5/stm32u5_extra.dtsi:19 */
			gpio-controller;              /* in zephyr/dts/arm/st/u5/stm32u5_extra.dtsi:20 */
			#gpio-cells = < 0x2 >;        /* in zephyr/dts/arm/st/u5/stm32u5_extra.dtsi:21 */
			reg = < 0x42021400 0x400 >;   /* in zephyr/dts/arm/st/u5/stm32u5_extra.dtsi:22 */
			clocks = < &rcc 0x8c 0x20 >;  /* in zephyr/dts/arm/st/u5/stm32u5_extra.dtsi:23 */
			phandle = < 0x35 >;           /* in zephyr/dts/arm/st/u5/stm32u5_extra.dtsi:83 */
		};

		/* node '/soc/gpio@42022000' defined in zephyr/dts/arm/st/u5/stm32u5_extra.dtsi:26 */
		gpioi: gpio@42022000 {
			compatible = "st,stm32-gpio"; /* in zephyr/dts/arm/st/u5/stm32u5_extra.dtsi:27 */
			gpio-controller;              /* in zephyr/dts/arm/st/u5/stm32u5_extra.dtsi:28 */
			#gpio-cells = < 0x2 >;        /* in zephyr/dts/arm/st/u5/stm32u5_extra.dtsi:29 */
			reg = < 0x42022000 0x400 >;   /* in zephyr/dts/arm/st/u5/stm32u5_extra.dtsi:30 */
			clocks = < &rcc 0x8c 0x100 >; /* in zephyr/dts/arm/st/u5/stm32u5_extra.dtsi:31 */
		};

		/* node '/soc/sdmmc@420c8c00' defined in zephyr/dts/arm/st/u5/stm32u5_extra.dtsi:34 */
		sdmmc2: sdmmc@420c8c00 {
			compatible = "st,stm32-sdmmc";     /* in zephyr/dts/arm/st/u5/stm32u5_extra.dtsi:35 */
			reg = < 0x420c8c00 0x400 >;        /* in zephyr/dts/arm/st/u5/stm32u5_extra.dtsi:36 */
			clocks = < &rcc 0x8c 0x10000000 >,
			         < &rcc 0x6 0xe00e4 >;     /* in zephyr/dts/arm/st/u5/stm32u5_extra.dtsi:37 */
			resets = < &rctl 0xc9c >;          /* in zephyr/dts/arm/st/u5/stm32u5_extra.dtsi:39 */
			interrupts = < 0x4f 0x0 >;         /* in zephyr/dts/arm/st/u5/stm32u5_extra.dtsi:40 */
			status = "disabled";               /* in zephyr/dts/arm/st/u5/stm32u5_extra.dtsi:41 */
		};

		/* node '/soc/memory-controller@420d0400' defined in zephyr/dts/arm/st/u5/stm32u5_extra.dtsi:44 */
		fmc: memory-controller@420d0400 {
			compatible = "st,stm32-fmc"; /* in zephyr/dts/arm/st/u5/stm32u5_extra.dtsi:45 */
			reg = < 0x420d0400 0x400 >;  /* in zephyr/dts/arm/st/u5/stm32u5_extra.dtsi:46 */
			clocks = < &rcc 0x90 0x1 >;  /* in zephyr/dts/arm/st/u5/stm32u5_extra.dtsi:47 */
			status = "disabled";         /* in zephyr/dts/arm/st/u5/stm32u5_extra.dtsi:48 */

			/* node '/soc/memory-controller@420d0400/sram' defined in zephyr/dts/arm/st/u5/stm32u5_extra.dtsi:50 */
			sram {
				compatible = "st,stm32-fmc-nor-psram"; /* in zephyr/dts/arm/st/u5/stm32u5_extra.dtsi:51 */
				#address-cells = < 0x1 >;              /* in zephyr/dts/arm/st/u5/stm32u5_extra.dtsi:52 */
				#size-cells = < 0x0 >;                 /* in zephyr/dts/arm/st/u5/stm32u5_extra.dtsi:53 */
				status = "disabled";                   /* in zephyr/dts/arm/st/u5/stm32u5_extra.dtsi:54 */
			};
		};

		/* node '/soc/ucpd@4000dc00' defined in zephyr/dts/arm/st/u5/stm32u5_extra.dtsi:71 */
		ucpd1: ucpd@4000dc00 {
			compatible = "st,stm32-ucpd";    /* in zephyr/dts/arm/st/u5/stm32u5_extra.dtsi:72 */
			reg = < 0x4000dc00 0x400 >;      /* in zephyr/dts/arm/st/u5/stm32u5_extra.dtsi:73 */
			clocks = < &rcc 0x9c 0x800000 >; /* in zephyr/dts/arm/st/u5/stm32u5_extra.dtsi:74 */
			interrupts = < 0x6a 0x0 >;       /* in zephyr/dts/arm/st/u5/stm32u5_extra.dtsi:75 */
			status = "disabled";             /* in zephyr/dts/arm/st/u5/stm32u5_extra.dtsi:76 */
		};

		/* node '/soc/otgfs@42040000' defined in zephyr/dts/arm/st/u5/stm32u5_usbotg_fs.dtsi:12 */
		usbotg_fs: zephyr_udc0: otgfs@42040000 {
			compatible = "st,stm32-otgfs";                           /* in zephyr/dts/arm/st/u5/stm32u5_usbotg_fs.dtsi:13 */
			reg = < 0x42040000 0x80000 >;                            /* in zephyr/dts/arm/st/u5/stm32u5_usbotg_fs.dtsi:14 */
			interrupts = < 0x49 0x0 >;                               /* in zephyr/dts/arm/st/u5/stm32u5_usbotg_fs.dtsi:15 */
			interrupt-names = "otgfs";                               /* in zephyr/dts/arm/st/u5/stm32u5_usbotg_fs.dtsi:16 */
			num-bidir-endpoints = < 0x6 >;                           /* in zephyr/dts/arm/st/u5/stm32u5_usbotg_fs.dtsi:17 */
			ram-size = < 0x500 >;                                    /* in zephyr/dts/arm/st/u5/stm32u5_usbotg_fs.dtsi:18 */
			maximum-speed = "full-speed";                            /* in zephyr/dts/arm/st/u5/stm32u5_usbotg_fs.dtsi:19 */
			clocks = < &rcc 0x8c 0x4000 >,
			         < &rcc 0x6 0x3a00e0 >;                          /* in zephyr/dts/arm/st/u5/stm32u5_usbotg_fs.dtsi:20 */
			phys = < &otgfs_phy >;                                   /* in zephyr/dts/arm/st/u5/stm32u5_usbotg_fs.dtsi:22 */
			pinctrl-0 = < &usb_otg_fs_dm_pa11 &usb_otg_fs_dp_pa12 >; /* in zephyr/boards/st/b_u585i_iot02a/b_u585i_iot02a-common.dtsi:253 */
			pinctrl-names = "default";                               /* in zephyr/boards/st/b_u585i_iot02a/b_u585i_iot02a-common.dtsi:254 */
			status = "okay";                                         /* in zephyr/boards/st/b_u585i_iot02a/b_u585i_iot02a-common.dtsi:255 */
		};

		/* node '/soc/aes@420c0000' defined in zephyr/dts/arm/st/u5/stm32u5_crypt.dtsi:9 */
		aes: aes@420c0000 {
			compatible = "st,stm32-aes";    /* in zephyr/dts/arm/st/u5/stm32u5_crypt.dtsi:10 */
			reg = < 0x420c0000 0x400 >;     /* in zephyr/dts/arm/st/u5/stm32u5_crypt.dtsi:11 */
			clocks = < &rcc 0x8c 0x10000 >; /* in zephyr/dts/arm/st/u5/stm32u5_crypt.dtsi:12 */
			resets = < &rctl 0xc90 >;       /* in zephyr/dts/arm/st/u5/stm32u5_crypt.dtsi:13 */
			interrupts = < 0x5d 0x0 >;      /* in zephyr/dts/arm/st/u5/stm32u5_crypt.dtsi:14 */
			status = "okay";                /* in zephyr/boards/st/b_u585i_iot02a/b_u585i_iot02a-common.dtsi:249 */
		};
	};

	/* node '/cpus' defined in zephyr/dts/arm/st/u5/stm32u5.dtsi:32 */
	cpus {
		#address-cells = < 0x1 >; /* in zephyr/dts/arm/st/u5/stm32u5.dtsi:33 */
		#size-cells = < 0x0 >;    /* in zephyr/dts/arm/st/u5/stm32u5.dtsi:34 */

		/* node '/cpus/cpu@0' defined in zephyr/dts/arm/st/u5/stm32u5.dtsi:36 */
		cpu0: cpu@0 {
			device_type = "cpu";                         /* in zephyr/dts/arm/st/u5/stm32u5.dtsi:37 */
			compatible = "arm,cortex-m33";               /* in zephyr/dts/arm/st/u5/stm32u5.dtsi:38 */
			reg = < 0x0 >;                               /* in zephyr/dts/arm/st/u5/stm32u5.dtsi:39 */
			#address-cells = < 0x1 >;                    /* in zephyr/dts/arm/st/u5/stm32u5.dtsi:40 */
			#size-cells = < 0x1 >;                       /* in zephyr/dts/arm/st/u5/stm32u5.dtsi:41 */
			cpu-power-states = < &stop0 &stop1 &stop2 >; /* in zephyr/dts/arm/st/u5/stm32u5.dtsi:42 */

			/* node '/cpus/cpu@0/mpu@e000ed90' defined in zephyr/dts/arm/st/u5/stm32u5.dtsi:44 */
			mpu: mpu@e000ed90 {
				compatible = "arm,armv8m-mpu"; /* in zephyr/dts/arm/st/u5/stm32u5.dtsi:45 */
				reg = < 0xe000ed90 0x40 >;     /* in zephyr/dts/arm/st/u5/stm32u5.dtsi:46 */
			};
		};

		/* node '/cpus/power-states' defined in zephyr/dts/arm/st/u5/stm32u5.dtsi:50 */
		power-states {

			/* node '/cpus/power-states/state0' defined in zephyr/dts/arm/st/u5/stm32u5.dtsi:51 */
			stop0: state0 {
				compatible = "zephyr,power-state";    /* in zephyr/dts/arm/st/u5/stm32u5.dtsi:52 */
				power-state-name = "suspend-to-idle"; /* in zephyr/dts/arm/st/u5/stm32u5.dtsi:53 */
				substate-id = < 0x1 >;                /* in zephyr/dts/arm/st/u5/stm32u5.dtsi:54 */
				min-residency-us = < 0x64 >;          /* in zephyr/dts/arm/st/u5/stm32u5.dtsi:55 */
				phandle = < 0x39 >;                   /* in zephyr/dts/arm/st/u5/stm32u5.dtsi:42 */
			};

			/* node '/cpus/power-states/state1' defined in zephyr/dts/arm/st/u5/stm32u5.dtsi:58 */
			stop1: state1 {
				compatible = "zephyr,power-state";    /* in zephyr/dts/arm/st/u5/stm32u5.dtsi:59 */
				power-state-name = "suspend-to-idle"; /* in zephyr/dts/arm/st/u5/stm32u5.dtsi:60 */
				substate-id = < 0x2 >;                /* in zephyr/dts/arm/st/u5/stm32u5.dtsi:61 */
				min-residency-us = < 0x1f4 >;         /* in zephyr/dts/arm/st/u5/stm32u5.dtsi:62 */
				phandle = < 0x3a >;                   /* in zephyr/dts/arm/st/u5/stm32u5.dtsi:42 */
			};

			/* node '/cpus/power-states/state2' defined in zephyr/dts/arm/st/u5/stm32u5.dtsi:65 */
			stop2: state2 {
				compatible = "zephyr,power-state";    /* in zephyr/dts/arm/st/u5/stm32u5.dtsi:66 */
				power-state-name = "suspend-to-idle"; /* in zephyr/dts/arm/st/u5/stm32u5.dtsi:67 */
				substate-id = < 0x3 >;                /* in zephyr/dts/arm/st/u5/stm32u5.dtsi:68 */
				min-residency-us = < 0x384 >;         /* in zephyr/dts/arm/st/u5/stm32u5.dtsi:69 */
				phandle = < 0x3b >;                   /* in zephyr/dts/arm/st/u5/stm32u5.dtsi:42 */
			};
		};
	};

	/* node '/memory@20000000' defined in zephyr/dts/arm/st/u5/stm32u5.dtsi:82 */
	sram0: memory@20000000 {
		compatible = "zephyr,memory-region",
		             "mmio-sram";            /* in zephyr/dts/arm/st/u5/stm32u5.dtsi:83 */
		zephyr,memory-region = "SRAM0";      /* in zephyr/dts/arm/st/u5/stm32u5.dtsi:84 */
		reg = < 0x20000000 0xc0000 >;        /* in zephyr/dts/arm/st/u5/stm32u575.dtsi:14 */
	};

	/* node '/clocks' defined in zephyr/dts/arm/st/u5/stm32u5.dtsi:87 */
	clocks {

		/* node '/clocks/clk-hse' defined in zephyr/dts/arm/st/u5/stm32u5.dtsi:88 */
		clk_hse: clk-hse {
			#clock-cells = < 0x0 >;            /* in zephyr/dts/arm/st/u5/stm32u5.dtsi:89 */
			compatible = "st,stm32-hse-clock"; /* in zephyr/dts/arm/st/u5/stm32u5.dtsi:90 */
			status = "disabled";               /* in zephyr/dts/arm/st/u5/stm32u5.dtsi:91 */
		};

		/* node '/clocks/clk-hsi' defined in zephyr/dts/arm/st/u5/stm32u5.dtsi:94 */
		clk_hsi: clk-hsi {
			#clock-cells = < 0x0 >;         /* in zephyr/dts/arm/st/u5/stm32u5.dtsi:95 */
			compatible = "fixed-clock";     /* in zephyr/dts/arm/st/u5/stm32u5.dtsi:96 */
			clock-frequency = < 0xf42400 >; /* in zephyr/dts/arm/st/u5/stm32u5.dtsi:97 */
			status = "disabled";            /* in zephyr/dts/arm/st/u5/stm32u5.dtsi:98 */
		};

		/* node '/clocks/clk-hsi48' defined in zephyr/dts/arm/st/u5/stm32u5.dtsi:101 */
		clk_hsi48: clk-hsi48 {
			#clock-cells = < 0x0 >;          /* in zephyr/dts/arm/st/u5/stm32u5.dtsi:102 */
			compatible = "fixed-clock";      /* in zephyr/dts/arm/st/u5/stm32u5.dtsi:103 */
			clock-frequency = < 0x2dc6c00 >; /* in zephyr/dts/arm/st/u5/stm32u5.dtsi:104 */
			status = "okay";                 /* in zephyr/boards/st/b_u585i_iot02a/b_u585i_iot02a-common.dtsi:57 */
		};

		/* node '/clocks/clk-msis' defined in zephyr/dts/arm/st/u5/stm32u5.dtsi:108 */
		clk_msis: clk-msis {
			#clock-cells = < 0x0 >;              /* in zephyr/dts/arm/st/u5/stm32u5.dtsi:109 */
			compatible = "st,stm32u5-msi-clock"; /* in zephyr/dts/arm/st/u5/stm32u5.dtsi:110 */
			status = "okay";                     /* in zephyr/boards/st/b_u585i_iot02a/b_u585i_iot02a-common.dtsi:65 */
			msi-range = < 0x4 >;                 /* in zephyr/boards/st/b_u585i_iot02a/b_u585i_iot02a-common.dtsi:66 */
			msi-pll-mode;                        /* in zephyr/boards/st/b_u585i_iot02a/b_u585i_iot02a-common.dtsi:67 */
			phandle = < 0x3c >;                  /* in zephyr/boards/st/b_u585i_iot02a/b_u585i_iot02a-common.dtsi:75 */
		};

		/* node '/clocks/clk-msik' defined in zephyr/dts/arm/st/u5/stm32u5.dtsi:115 */
		clk_msik: clk-msik {
			#clock-cells = < 0x0 >;              /* in zephyr/dts/arm/st/u5/stm32u5.dtsi:116 */
			compatible = "st,stm32u5-msi-clock"; /* in zephyr/dts/arm/st/u5/stm32u5.dtsi:117 */
			msi-range = < 0x4 >;                 /* in zephyr/dts/arm/st/u5/stm32u5.dtsi:118 */
			status = "disabled";                 /* in zephyr/dts/arm/st/u5/stm32u5.dtsi:119 */
		};

		/* node '/clocks/clk-lse' defined in zephyr/dts/arm/st/u5/stm32u5.dtsi:122 */
		clk_lse: clk-lse {
			#clock-cells = < 0x0 >;            /* in zephyr/dts/arm/st/u5/stm32u5.dtsi:123 */
			compatible = "st,stm32-lse-clock"; /* in zephyr/dts/arm/st/u5/stm32u5.dtsi:124 */
			clock-frequency = < 0x8000 >;      /* in zephyr/dts/arm/st/u5/stm32u5.dtsi:125 */
			driving-capability = < 0x2 >;      /* in zephyr/dts/arm/st/u5/stm32u5.dtsi:126 */
			status = "okay";                   /* in zephyr/boards/st/b_u585i_iot02a/b_u585i_iot02a-common.dtsi:61 */
		};

		/* node '/clocks/clk-lsi' defined in zephyr/dts/arm/st/u5/stm32u5.dtsi:130 */
		clk_lsi: clk-lsi {
			#clock-cells = < 0x0 >;       /* in zephyr/dts/arm/st/u5/stm32u5.dtsi:131 */
			compatible = "fixed-clock";   /* in zephyr/dts/arm/st/u5/stm32u5.dtsi:132 */
			clock-frequency = < 0x7d00 >; /* in zephyr/dts/arm/st/u5/stm32u5.dtsi:133 */
			status = "disabled";          /* in zephyr/dts/arm/st/u5/stm32u5.dtsi:134 */
		};

		/* node '/clocks/pll' defined in zephyr/dts/arm/st/u5/stm32u5.dtsi:137 */
		pll1: pll: pll {
			#clock-cells = < 0x0 >;              /* in zephyr/dts/arm/st/u5/stm32u5.dtsi:138 */
			compatible = "st,stm32u5-pll-clock"; /* in zephyr/dts/arm/st/u5/stm32u5.dtsi:139 */
			div-m = < 0x1 >;                     /* in zephyr/boards/st/b_u585i_iot02a/b_u585i_iot02a-common.dtsi:71 */
			mul-n = < 0x50 >;                    /* in zephyr/boards/st/b_u585i_iot02a/b_u585i_iot02a-common.dtsi:72 */
			div-q = < 0x2 >;                     /* in zephyr/boards/st/b_u585i_iot02a/b_u585i_iot02a-common.dtsi:73 */
			div-r = < 0x2 >;                     /* in zephyr/boards/st/b_u585i_iot02a/b_u585i_iot02a-common.dtsi:74 */
			clocks = < &clk_msis >;              /* in zephyr/boards/st/b_u585i_iot02a/b_u585i_iot02a-common.dtsi:75 */
			status = "okay";                     /* in zephyr/boards/st/b_u585i_iot02a/b_u585i_iot02a-common.dtsi:76 */
			phandle = < 0x2 >;                   /* in zephyr/boards/st/b_u585i_iot02a/b_u585i_iot02a-common.dtsi:80 */
		};

		/* node '/clocks/pll2' defined in zephyr/dts/arm/st/u5/stm32u5.dtsi:143 */
		pll2: pll2 {
			#clock-cells = < 0x0 >;              /* in zephyr/dts/arm/st/u5/stm32u5.dtsi:144 */
			compatible = "st,stm32u5-pll-clock"; /* in zephyr/dts/arm/st/u5/stm32u5.dtsi:145 */
			status = "disabled";                 /* in zephyr/dts/arm/st/u5/stm32u5.dtsi:146 */
		};

		/* node '/clocks/pll3' defined in zephyr/dts/arm/st/u5/stm32u5.dtsi:149 */
		pll3: pll3 {
			#clock-cells = < 0x0 >;              /* in zephyr/dts/arm/st/u5/stm32u5.dtsi:150 */
			compatible = "st,stm32u5-pll-clock"; /* in zephyr/dts/arm/st/u5/stm32u5.dtsi:151 */
			status = "disabled";                 /* in zephyr/dts/arm/st/u5/stm32u5.dtsi:152 */
		};
	};

	/* node '/mcos' defined in zephyr/dts/arm/st/u5/stm32u5.dtsi:156 */
	mcos {

		/* node '/mcos/mco1' defined in zephyr/dts/arm/st/u5/stm32u5.dtsi:157 */
		mco1: mco1 {
			compatible = "st,stm32-clock-mco"; /* in zephyr/dts/arm/st/u5/stm32u5.dtsi:158 */
			clock-names = "clksel";            /* in zephyr/dts/arm/st/u5/stm32u5.dtsi:159 */
			status = "disabled";               /* in zephyr/dts/arm/st/u5/stm32u5.dtsi:160 */
		};
	};

	/* node '/swj_port' defined in zephyr/dts/arm/st/u5/stm32u5.dtsi:1060 */
	swj_port: swj_port {
		compatible = "swj-connector";                                                                    /* in zephyr/dts/arm/st/u5/stm32u5.dtsi:1061 */
		pinctrl-0 = < &debug_jtms_swdio_pa13 &debug_jtck_swclk_pa14 &debug_jtdi_pa15 &debug_jtdo_swo_pb3
		              &debug_njtrst_pb4 >;                                                               /* in zephyr/dts/arm/st/u5/stm32u5.dtsi:1062 */
		pinctrl-1 = < &analog_pa13 &analog_pa14 &analog_pa15 &analog_pb3 &analog_pb4 >;                  /* in zephyr/dts/arm/st/u5/stm32u5.dtsi:1065 */
		pinctrl-names = "default",
		                "sleep";                                                                         /* in zephyr/dts/arm/st/u5/stm32u5.dtsi:1067 */
	};

	/* node '/dietemp' defined in zephyr/dts/arm/st/u5/stm32u5.dtsi:1070 */
	die_temp: dietemp {
		compatible = "st,stm32-temp-cal"; /* in zephyr/dts/arm/st/u5/stm32u5.dtsi:1071 */
		nvmem-cells = < &ts_cal1_otp >,
		              < &ts_cal2_otp >;   /* in zephyr/dts/arm/st/u5/stm32u5.dtsi:1072 */
		nvmem-cell-names = "TS_CAL1",
		                   "TS_CAL2";     /* in zephyr/dts/arm/st/u5/stm32u5.dtsi:1073 */
		ts-cal1-temp = < 0x1e >;          /* in zephyr/dts/arm/st/u5/stm32u5.dtsi:1074 */
		ts-cal2-temp = < 0x82 >;          /* in zephyr/dts/arm/st/u5/stm32u5.dtsi:1075 */
		ts-cal-vrefanalog = < 0xbb8 >;    /* in zephyr/dts/arm/st/u5/stm32u5.dtsi:1076 */
		ts-cal-resolution = < 0xe >;      /* in zephyr/dts/arm/st/u5/stm32u5.dtsi:1077 */
		io-channels = < &adc1 0x13 >;     /* in zephyr/dts/arm/st/u5/stm32u5.dtsi:1078 */
		status = "okay";                  /* in zephyr/boards/st/b_u585i_iot02a/b_u585i_iot02a.dts:114 */
	};

	/* node '/vref_1' defined in zephyr/dts/arm/st/u5/stm32u5.dtsi:1082 */
	vref1: vref_1 {
		compatible = "st,stm32-vref";     /* in zephyr/dts/arm/st/u5/stm32u5.dtsi:1083 */
		nvmem-cells = < &vrefint_otp >;   /* in zephyr/dts/arm/st/u5/stm32u5.dtsi:1084 */
		vrefint-cal-mv = < 0xbb8 >;       /* in zephyr/dts/arm/st/u5/stm32u5.dtsi:1085 */
		vrefint-cal-resolution = < 0xe >; /* in zephyr/dts/arm/st/u5/stm32u5.dtsi:1086 */
		io-channels = < &adc1 0x0 >;      /* in zephyr/dts/arm/st/u5/stm32u5.dtsi:1087 */
		status = "okay";                  /* in zephyr/boards/st/b_u585i_iot02a/b_u585i_iot02a-common.dtsi:295 */
	};

	/* node '/vref_4' defined in zephyr/dts/arm/st/u5/stm32u5.dtsi:1091 */
	vref4: vref_4 {
		compatible = "st,stm32-vref";     /* in zephyr/dts/arm/st/u5/stm32u5.dtsi:1092 */
		nvmem-cells = < &vrefint_otp >;   /* in zephyr/dts/arm/st/u5/stm32u5.dtsi:1093 */
		vrefint-cal-mv = < 0xbb8 >;       /* in zephyr/dts/arm/st/u5/stm32u5.dtsi:1094 */
		vrefint-cal-resolution = < 0xe >; /* in zephyr/dts/arm/st/u5/stm32u5.dtsi:1095 */
		io-channels = < &adc4 0x0 >;      /* in zephyr/dts/arm/st/u5/stm32u5.dtsi:1096 */
		status = "disabled";              /* in zephyr/dts/arm/st/u5/stm32u5.dtsi:1097 */
	};

	/* node '/vbat_1' defined in zephyr/dts/arm/st/u5/stm32u5.dtsi:1100 */
	vbat1: vbat_1 {
		compatible = "st,stm32-vbat"; /* in zephyr/dts/arm/st/u5/stm32u5.dtsi:1101 */
		ratio = < 0x4 >;              /* in zephyr/dts/arm/st/u5/stm32u5.dtsi:1102 */
		io-channels = < &adc1 0x12 >; /* in zephyr/dts/arm/st/u5/stm32u5.dtsi:1103 */
		status = "disabled";          /* in zephyr/dts/arm/st/u5/stm32u5.dtsi:1104 */
	};

	/* node '/vbat_4' defined in zephyr/dts/arm/st/u5/stm32u5.dtsi:1107 */
	vbat4: vbat_4 {
		compatible = "st,stm32-vbat"; /* in zephyr/dts/arm/st/u5/stm32u5.dtsi:1108 */
		ratio = < 0x4 >;              /* in zephyr/dts/arm/st/u5/stm32u5.dtsi:1109 */
		io-channels = < &adc4 0xe >;  /* in zephyr/dts/arm/st/u5/stm32u5.dtsi:1110 */
		status = "okay";              /* in zephyr/boards/st/b_u585i_iot02a/b_u585i_iot02a-common.dtsi:299 */
	};

	/* node '/smbus1' defined in zephyr/dts/arm/st/u5/stm32u5.dtsi:1114 */
	smbus1: smbus1 {
		compatible = "st,stm32-smbus"; /* in zephyr/dts/arm/st/u5/stm32u5.dtsi:1115 */
		#address-cells = < 0x1 >;      /* in zephyr/dts/arm/st/u5/stm32u5.dtsi:1116 */
		#size-cells = < 0x0 >;         /* in zephyr/dts/arm/st/u5/stm32u5.dtsi:1117 */
		i2c = < &i2c1 >;               /* in zephyr/dts/arm/st/u5/stm32u5.dtsi:1118 */
		status = "disabled";           /* in zephyr/dts/arm/st/u5/stm32u5.dtsi:1119 */
	};

	/* node '/smbus2' defined in zephyr/dts/arm/st/u5/stm32u5.dtsi:1122 */
	smbus2: smbus2 {
		compatible = "st,stm32-smbus"; /* in zephyr/dts/arm/st/u5/stm32u5.dtsi:1123 */
		#address-cells = < 0x1 >;      /* in zephyr/dts/arm/st/u5/stm32u5.dtsi:1124 */
		#size-cells = < 0x0 >;         /* in zephyr/dts/arm/st/u5/stm32u5.dtsi:1125 */
		i2c = < &i2c2 >;               /* in zephyr/dts/arm/st/u5/stm32u5.dtsi:1126 */
		status = "disabled";           /* in zephyr/dts/arm/st/u5/stm32u5.dtsi:1127 */
	};

	/* node '/smbus3' defined in zephyr/dts/arm/st/u5/stm32u5.dtsi:1130 */
	smbus3: smbus3 {
		compatible = "st,stm32-smbus"; /* in zephyr/dts/arm/st/u5/stm32u5.dtsi:1131 */
		#address-cells = < 0x1 >;      /* in zephyr/dts/arm/st/u5/stm32u5.dtsi:1132 */
		#size-cells = < 0x0 >;         /* in zephyr/dts/arm/st/u5/stm32u5.dtsi:1133 */
		i2c = < &i2c3 >;               /* in zephyr/dts/arm/st/u5/stm32u5.dtsi:1134 */
		status = "disabled";           /* in zephyr/dts/arm/st/u5/stm32u5.dtsi:1135 */
	};

	/* node '/smbus4' defined in zephyr/dts/arm/st/u5/stm32u5.dtsi:1138 */
	smbus4: smbus4 {
		compatible = "st,stm32-smbus"; /* in zephyr/dts/arm/st/u5/stm32u5.dtsi:1139 */
		#address-cells = < 0x1 >;      /* in zephyr/dts/arm/st/u5/stm32u5.dtsi:1140 */
		#size-cells = < 0x0 >;         /* in zephyr/dts/arm/st/u5/stm32u5.dtsi:1141 */
		i2c = < &i2c4 >;               /* in zephyr/dts/arm/st/u5/stm32u5.dtsi:1142 */
		status = "disabled";           /* in zephyr/dts/arm/st/u5/stm32u5.dtsi:1143 */
	};

	/* node '/otgfs_phy' defined in zephyr/dts/arm/st/u5/stm32u5_usbotg_fs.dtsi:27 */
	otgfs_phy: otgfs_phy {
		compatible = "usb-nop-xceiv"; /* in zephyr/dts/arm/st/u5/stm32u5_usbotg_fs.dtsi:28 */
		#phy-cells = < 0x0 >;         /* in zephyr/dts/arm/st/u5/stm32u5_usbotg_fs.dtsi:29 */
		phandle = < 0x36 >;           /* in zephyr/dts/arm/st/u5/stm32u5_usbotg_fs.dtsi:22 */
	};

	/* node '/memory@28000000' defined in zephyr/dts/arm/st/u5/stm32u575.dtsi:17 */
	sram1: memory@28000000 {
		reg = < 0x28000000 0x4000 >; /* in zephyr/dts/arm/st/u5/stm32u575.dtsi:19 */
	};

	/* node '/connector' defined in zephyr/boards/st/b_u585i_iot02a/arduino_r3_connector.dtsi:10 */
	arduino_header: connector {
		compatible = "arduino-header-r3";          /* in zephyr/boards/st/b_u585i_iot02a/arduino_r3_connector.dtsi:11 */
		#gpio-cells = < 0x2 >;                     /* in zephyr/boards/st/b_u585i_iot02a/arduino_r3_connector.dtsi:12 */
		gpio-map-mask = < 0xffffffff 0xffffffc0 >; /* in zephyr/boards/st/b_u585i_iot02a/arduino_r3_connector.dtsi:13 */
		gpio-map-pass-thru = < 0x0 0x3f >;         /* in zephyr/boards/st/b_u585i_iot02a/arduino_r3_connector.dtsi:14 */
		gpio-map = < 0x0 0x0 &gpioc 0x0 0x0 >,
		           < 0x1 0x0 &gpioc 0x2 0x0 >,
		           < 0x2 0x0 &gpioc 0x4 0x0 >,
		           < 0x3 0x0 &gpioc 0x5 0x0 >,
		           < 0x4 0x0 &gpioa 0x7 0x0 >,
		           < 0x5 0x0 &gpiob 0x0 0x0 >,
		           < 0x6 0x0 &gpiod 0x8 0x0 >,
		           < 0x7 0x0 &gpiod 0x9 0x0 >,
		           < 0x8 0x0 &gpiod 0xf 0x0 >,
		           < 0x9 0x0 &gpiob 0x2 0x0 >,
		           < 0xa 0x0 &gpioe 0x7 0x0 >,
		           < 0xb 0x0 &gpioe 0x0 0x0 >,
		           < 0xc 0x0 &gpiob 0x6 0x0 >,
		           < 0xd 0x0 &gpiof 0xd 0x0 >,
		           < 0xe 0x0 &gpioc 0x1 0x0 >,
		           < 0xf 0x0 &gpioa 0x8 0x0 >,
		           < 0x10 0x0 &gpioe 0xc 0x0 >,
		           < 0x11 0x0 &gpioe 0xf 0x0 >,
		           < 0x12 0x0 &gpioe 0xe 0x0 >,
		           < 0x13 0x0 &gpioe 0xd 0x0 >,
		           < 0x14 0x0 &gpiob 0x9 0x0 >,
		           < 0x15 0x0 &gpiob 0x8 0x0 >;    /* in zephyr/boards/st/b_u585i_iot02a/arduino_r3_connector.dtsi:15 */
	};

	/* node '/leds' defined in zephyr/boards/st/b_u585i_iot02a/b_u585i_iot02a-common.dtsi:16 */
	leds {
		compatible = "gpio-leds"; /* in zephyr/boards/st/b_u585i_iot02a/b_u585i_iot02a-common.dtsi:17 */

		/* node '/leds/led_1' defined in zephyr/boards/st/b_u585i_iot02a/b_u585i_iot02a-common.dtsi:19 */
		green_led_1: led_1 {
			gpios = < &gpioh 0x7 0x1 >; /* in zephyr/boards/st/b_u585i_iot02a/b_u585i_iot02a-common.dtsi:20 */
			label = "User LD7";         /* in zephyr/boards/st/b_u585i_iot02a/b_u585i_iot02a-common.dtsi:21 */
		};

		/* node '/leds/led_3' defined in zephyr/boards/st/b_u585i_iot02a/b_u585i_iot02a-common.dtsi:24 */
		red_led_1: led_3 {
			gpios = < &gpioh 0x6 0x1 >; /* in zephyr/boards/st/b_u585i_iot02a/b_u585i_iot02a-common.dtsi:25 */
			label = "User LD6";         /* in zephyr/boards/st/b_u585i_iot02a/b_u585i_iot02a-common.dtsi:26 */
		};
	};

	/* node '/gpio_keys' defined in zephyr/boards/st/b_u585i_iot02a/b_u585i_iot02a-common.dtsi:30 */
	gpio_keys {
		compatible = "gpio-keys"; /* in zephyr/boards/st/b_u585i_iot02a/b_u585i_iot02a-common.dtsi:31 */

		/* node '/gpio_keys/button' defined in zephyr/boards/st/b_u585i_iot02a/b_u585i_iot02a-common.dtsi:33 */
		user_button: button {
			label = "User";              /* in zephyr/boards/st/b_u585i_iot02a/b_u585i_iot02a-common.dtsi:34 */
			gpios = < &gpioc 0xd 0x11 >; /* in zephyr/boards/st/b_u585i_iot02a/b_u585i_iot02a-common.dtsi:35 */
			zephyr,code = < 0xb >;       /* in zephyr/boards/st/b_u585i_iot02a/b_u585i_iot02a-common.dtsi:36 */
		};
	};

	/* node '/memory@90000000' defined in zephyr/boards/st/b_u585i_iot02a/b_u585i_iot02a-common.dtsi:48 */
	psram: memory@90000000 {
		compatible = "zephyr,memory-region"; /* in zephyr/boards/st/b_u585i_iot02a/b_u585i_iot02a-common.dtsi:49 */
		reg = < 0x90000000 0x800000 >;       /* in zephyr/boards/st/b_u585i_iot02a/b_u585i_iot02a-common.dtsi:50 */
		zephyr,memory-region = "PSRAM";      /* in zephyr/boards/st/b_u585i_iot02a/b_u585i_iot02a-common.dtsi:51 */
		zephyr,memory-attr = < 0x100000 >;   /* in zephyr/boards/st/b_u585i_iot02a/b_u585i_iot02a-common.dtsi:52 */
	};

	/* node '/memory@70000000' defined in zephyr/boards/st/b_u585i_iot02a/b_u585i_iot02a.dts:33 */
	octo_nor: memory@70000000 {
		compatible = "zephyr,memory-region"; /* in zephyr/boards/st/b_u585i_iot02a/b_u585i_iot02a.dts:34 */
		reg = < 0x70000000 0x4000000 >;      /* in zephyr/boards/st/b_u585i_iot02a/b_u585i_iot02a.dts:35 */
		zephyr,memory-region = "EXTMEM";     /* in zephyr/boards/st/b_u585i_iot02a/b_u585i_iot02a.dts:36 */
		zephyr,memory-attr = < 0x1000000 >;  /* in zephyr/boards/st/b_u585i_iot02a/b_u585i_iot02a.dts:38 */
	};

	/* node '/example-sensor' defined in my-app/app/boards/b_u585i_iot02a.overlay:13 */
	example_sensor: example-sensor {
		compatible = "zephyr,example-sensor"; /* in my-app/app/boards/b_u585i_iot02a.overlay:14 */
		input-gpios = < &gpioc 0xd 0x11 >;    /* in my-app/app/boards/b_u585i_iot02a.overlay:15 */
	};

	/* node '/blink-led' defined in my-app/app/boards/b_u585i_iot02a.overlay:18 */
	blink_led: blink-led {
		compatible = "blink-gpio-led";  /* in my-app/app/boards/b_u585i_iot02a.overlay:19 */
		led-gpios = < &gpiob 0xd 0x0 >; /* in my-app/app/boards/b_u585i_iot02a.overlay:20 */
		blink-period-ms = < 0x3e8 >;    /* in my-app/app/boards/b_u585i_iot02a.overlay:21 */
	};
};
